AUTOSAR XML (schema 4-0-3)
standard types defined: uint8, boolean, Boolean, UInt16, UInt8
package /AUTOSAR_Platform/DataConstrs
  range DC_Boolean: raw 0..1
  range DC_UInt16: raw 0..65535
  range DC_UInt8: raw 0..255
package /DataTypes/Units
  unit NoUnit: display-name=NoUnit, factor-si-to-unit=0, offset-si-to-unit=0
package /PATAC/Facility/DataTypes/Implementation
  compu method COMPU_Boolean: 0=FALSE, 1=TRUE; unit Implementation/NoUnit
  unit NoUnit: factor-si-to-unit=1, offset-si-to-unit=0
package /PATAC/MSM/ComponentTypes
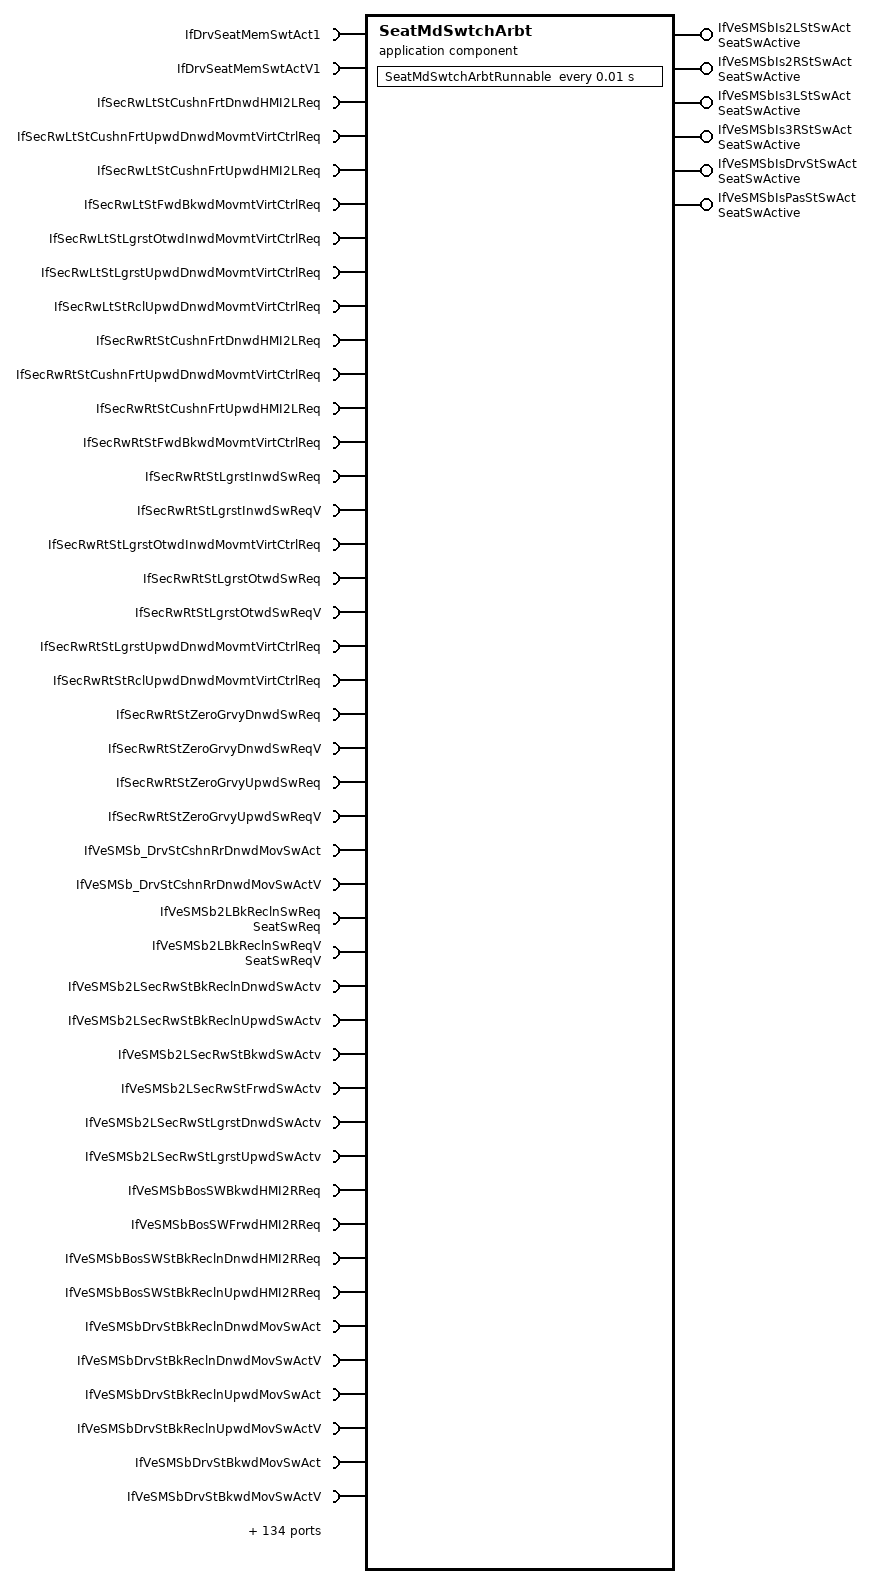
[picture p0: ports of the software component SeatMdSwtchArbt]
  application sw component type SeatMdSwtchArbt
    6 x provide port, all with provided-interface=SeatSwActive:
      IfVeSMSbIs2LStSwAct: nonqueued-sender-com-spec{data-element=SeatSwActive/Val, init-value=0}
      IfVeSMSbIs2RStSwAct: nonqueued-sender-com-spec{data-element=SeatSwActive/Val, init-value=ComSpec8990498a_9172c788e1a27a03:0}
      IfVeSMSbIs3LStSwAct: nonqueued-sender-com-spec{data-element=SeatSwActive/Val, init-value=ComSpec1be8b356_bff1fa270b850cb2:0}
      IfVeSMSbIs3RStSwAct: nonqueued-sender-com-spec{data-element=SeatSwActive/Val, init-value=ComSpec86b33b2c_4b4378d252844b5b:0}
      IfVeSMSbIsDrvStSwAct: nonqueued-sender-com-spec{data-element=SeatSwActive/Val, init-value=ComSpeccfea2e26_82ec98f59fb47201:0}
      IfVeSMSbIsPasStSwAct: nonqueued-sender-com-spec{data-element=SeatSwActive/Val, init-value=ComSpec83cefd09_a80dc45f2ed75e9c:0}
    178 x require port:
      IfDrvSeatMemSwtAct1: nonqueued-receiver-com-spec{data-element=IfDrvSeatMemSwtAct1/Val, filter=data-filter-type=ALWAYS, init-value=ComSpec097d2a70_c41c2d6baecec007:0}, required-interface=IfDrvSeatMemSwtAct1
      IfDrvSeatMemSwtActV1: nonqueued-receiver-com-spec{data-element=IfDrvSeatMemSwtActV1/Val, filter=data-filter-type=ALWAYS, init-value=ComSpece168664c_e10092eb753fba19:1}, required-interface=IfDrvSeatMemSwtActV1
      IfSecRwLtStCushnFrtDnwdHMI2LReq: nonqueued-receiver-com-spec{data-element=IfSecRwLtStCushnFrtDnwdHMI2LReq/Val, filter=data-filter-type=ALWAYS, init-value=0}, required-interface=IfSecRwLtStCushnFrtDnwdHMI2LReq
      IfSecRwLtStCushnFrtUpwdDnwdMovmtVirtCtrlReq: nonqueued-receiver-com-spec{data-element=IfSecRwLtStCushnFrtUpwdDnwdMovmtVirtCtrlReq/Val, filter=data-filter-type=ALWAYS, init-value=0}, required-interface=IfSecRwLtStCushnFrtUpwdDnwdMovmtVirtCtrlReq
      IfSecRwLtStCushnFrtUpwdHMI2LReq: nonqueued-receiver-com-spec{data-element=IfSecRwLtStCushnFrtUpwdHMI2LReq/Val, filter=data-filter-type=ALWAYS, init-value=0}, required-interface=IfSecRwLtStCushnFrtUpwdHMI2LReq
      IfSecRwLtStFwdBkwdMovmtVirtCtrlReq: nonqueued-receiver-com-spec{data-element=IfSecRwLtStFwdBkwdMovmtVirtCtrlReq/Val, filter=data-filter-type=ALWAYS, init-value=0}, required-interface=IfSecRwLtStFwdBkwdMovmtVirtCtrlReq
      IfSecRwLtStLgrstOtwdInwdMovmtVirtCtrlReq: nonqueued-receiver-com-spec{data-element=IfSecRwLtStLgrstOtwdInwdMovmtVirtCtrlReq/Val, filter=data-filter-type=ALWAYS, init-value=0}, required-interface=IfSecRwLtStLgrstOtwdInwdMovmtVirtCtrlReq
      IfSecRwLtStLgrstUpwdDnwdMovmtVirtCtrlReq: nonqueued-receiver-com-spec{data-element=IfSecRwLtStLgrstUpwdDnwdMovmtVirtCtrlReq/Val, filter=data-filter-type=ALWAYS, init-value=0}, required-interface=IfSecRwLtStLgrstUpwdDnwdMovmtVirtCtrlReq
      IfSecRwLtStRclUpwdDnwdMovmtVirtCtrlReq: nonqueued-receiver-com-spec{data-element=IfSecRwLtStRclUpwdDnwdMovmtVirtCtrlReq/Val, filter=data-filter-type=ALWAYS, init-value=0}, required-interface=IfSecRwLtStRclUpwdDnwdMovmtVirtCtrlReq
      IfSecRwRtStCushnFrtDnwdHMI2LReq: nonqueued-receiver-com-spec{data-element=IfSecRwRtStCushnFrtDnwdHMI2LReq/Val, filter=data-filter-type=ALWAYS, init-value=0}, required-interface=IfSecRwRtStCushnFrtDnwdHMI2LReq
      IfSecRwRtStCushnFrtUpwdDnwdMovmtVirtCtrlReq: nonqueued-receiver-com-spec{data-element=IfSecRwRtStCushnFrtUpwdDnwdMovmtVirtCtrlReq/Val, filter=data-filter-type=ALWAYS, init-value=0}, required-interface=IfSecRwRtStCushnFrtUpwdDnwdMovmtVirtCtrlReq
      IfSecRwRtStCushnFrtUpwdHMI2LReq: nonqueued-receiver-com-spec{data-element=IfSecRwRtStCushnFrtUpwdHMI2LReq/Val, filter=data-filter-type=ALWAYS, init-value=0}, required-interface=IfSecRwRtStCushnFrtUpwdHMI2LReq
      IfSecRwRtStFwdBkwdMovmtVirtCtrlReq: nonqueued-receiver-com-spec{data-element=IfSecRwRtStFwdBkwdMovmtVirtCtrlReq/Val, filter=data-filter-type=ALWAYS, init-value=0}, required-interface=IfSecRwRtStFwdBkwdMovmtVirtCtrlReq
      IfSecRwRtStLgrstInwdSwReq: nonqueued-receiver-com-spec{data-element=IfSecRwRtStLgrstInwdSwReq/Val, filter=data-filter-type=ALWAYS, init-value=0}, required-interface=IfSecRwRtStLgrstInwdSwReq
      IfSecRwRtStLgrstInwdSwReqV: nonqueued-receiver-com-spec{data-element=IfSecRwRtStLgrstInwdSwReqV/Val, filter=data-filter-type=ALWAYS, init-value=0}, required-interface=IfSecRwRtStLgrstInwdSwReqV
      IfSecRwRtStLgrstOtwdInwdMovmtVirtCtrlReq: nonqueued-receiver-com-spec{data-element=IfSecRwRtStLgrstOtwdInwdMovmtVirtCtrlReq/Val, filter=data-filter-type=ALWAYS, init-value=0}, required-interface=IfSecRwRtStLgrstOtwdInwdMovmtVirtCtrlReq
      IfSecRwRtStLgrstOtwdSwReq: nonqueued-receiver-com-spec{data-element=IfSecRwRtStLgrstOtwdSwReq/Val, filter=data-filter-type=ALWAYS, init-value=0}, required-interface=IfSecRwRtStLgrstOtwdSwReq
      IfSecRwRtStLgrstOtwdSwReqV: nonqueued-receiver-com-spec{data-element=IfSecRwRtStLgrstOtwdSwReqV/Val, filter=data-filter-type=ALWAYS, init-value=0}, required-interface=IfSecRwRtStLgrstOtwdSwReqV
      IfSecRwRtStLgrstUpwdDnwdMovmtVirtCtrlReq: nonqueued-receiver-com-spec{data-element=IfSecRwRtStLgrstUpwdDnwdMovmtVirtCtrlReq/Val, filter=data-filter-type=ALWAYS, init-value=0}, required-interface=IfSecRwRtStLgrstUpwdDnwdMovmtVirtCtrlReq
      IfSecRwRtStRclUpwdDnwdMovmtVirtCtrlReq: nonqueued-receiver-com-spec{data-element=IfSecRwRtStRclUpwdDnwdMovmtVirtCtrlReq/Val, filter=data-filter-type=ALWAYS, init-value=0}, required-interface=IfSecRwRtStRclUpwdDnwdMovmtVirtCtrlReq
      IfSecRwRtStZeroGrvyDnwdSwReq: nonqueued-receiver-com-spec{data-element=IfSecRwRtStZeroGrvyDnwdSwReq/Val, filter=data-filter-type=ALWAYS, init-value=0}, required-interface=IfSecRwRtStZeroGrvyDnwdSwReq
      IfSecRwRtStZeroGrvyDnwdSwReqV: nonqueued-receiver-com-spec{data-element=IfSecRwRtStZeroGrvyDnwdSwReqV/Val, filter=data-filter-type=ALWAYS, init-value=0}, required-interface=IfSecRwRtStZeroGrvyDnwdSwReqV
      IfSecRwRtStZeroGrvyUpwdSwReq: nonqueued-receiver-com-spec{data-element=IfSecRwRtStZeroGrvyUpwdSwReq/Val, filter=data-filter-type=ALWAYS, init-value=0}, required-interface=IfSecRwRtStZeroGrvyUpwdSwReq
      IfSecRwRtStZeroGrvyUpwdSwReqV: nonqueued-receiver-com-spec{data-element=IfSecRwRtStZeroGrvyUpwdSwReqV/Val, filter=data-filter-type=ALWAYS, init-value=0}, required-interface=IfSecRwRtStZeroGrvyUpwdSwReqV
      IfVeSMSb_DrvStCshnRrDnwdMovSwAct: nonqueued-receiver-com-spec{data-element=IfVeSMSb_DrvStCshnRrDnwdMovSwAct/Val, filter=data-filter-type=ALWAYS, init-value=0}, required-interface=IfVeSMSb_DrvStCshnRrDnwdMovSwAct
      IfVeSMSb_DrvStCshnRrDnwdMovSwActV: nonqueued-receiver-com-spec{data-element=IfVeSMSb_DrvStCshnRrDnwdMovSwActV/Val, filter=data-filter-type=ALWAYS, init-value=1}, required-interface=IfVeSMSb_DrvStCshnRrDnwdMovSwActV
      IfVeSMSb2LBkReclnSwReq: nonqueued-receiver-com-spec{data-element=SeatSwReq/Val, filter=data-filter-type=ALWAYS, init-value=ComSpec24bdc9f9_e94ae9a508735d5e:0}, required-interface=SeatSwReq
      IfVeSMSb2LBkReclnSwReqV: nonqueued-receiver-com-spec{data-element=SeatSwReqV/Val, filter=data-filter-type=ALWAYS, init-value=0}, required-interface=SeatSwReqV
      IfVeSMSb2LSecRwStBkReclnDnwdSwActv: nonqueued-receiver-com-spec{data-element=IfVeSMSb2LSecRwStBkReclnDnwdSwActv/Val, filter=data-filter-type=ALWAYS, init-value=0}, required-interface=IfVeSMSb2LSecRwStBkReclnDnwdSwActv
      IfVeSMSb2LSecRwStBkReclnUpwdSwActv: nonqueued-receiver-com-spec{data-element=IfVeSMSb2LSecRwStBkReclnUpwdSwActv/Val, filter=data-filter-type=ALWAYS, init-value=0}, required-interface=IfVeSMSb2LSecRwStBkReclnUpwdSwActv
      IfVeSMSb2LSecRwStBkwdSwActv: nonqueued-receiver-com-spec{data-element=IfVeSMSb2LSecRwStBkwdSwActv/Val, filter=data-filter-type=ALWAYS, init-value=0}, required-interface=IfVeSMSb2LSecRwStBkwdSwActv
      IfVeSMSb2LSecRwStFrwdSwActv: nonqueued-receiver-com-spec{data-element=IfVeSMSb2LSecRwStFrwdSwActv/Val, filter=data-filter-type=ALWAYS, init-value=0}, required-interface=IfVeSMSb2LSecRwStFrwdSwActv
      IfVeSMSb2LSecRwStLgrstDnwdSwActv: nonqueued-receiver-com-spec{data-element=IfVeSMSb2LSecRwStLgrstDnwdSwActv/Val, filter=data-filter-type=ALWAYS, init-value=0}, required-interface=IfVeSMSb2LSecRwStLgrstDnwdSwActv
      IfVeSMSb2LSecRwStLgrstUpwdSwActv: nonqueued-receiver-com-spec{data-element=IfVeSMSb2LSecRwStLgrstUpwdSwActv/Val, filter=data-filter-type=ALWAYS, init-value=0}, required-interface=IfVeSMSb2LSecRwStLgrstUpwdSwActv
      IfVeSMSbBosSWBkwdHMI2RReq: nonqueued-receiver-com-spec{data-element=IfVeSMSbBosSWBkwdHMI2RReq/Val, filter=data-filter-type=ALWAYS, init-value=0}, required-interface=IfVeSMSbBosSWBkwdHMI2RReq
      IfVeSMSbBosSWFrwdHMI2RReq: nonqueued-receiver-com-spec{data-element=IfVeSMSbBosSWFrwdHMI2RReq/Val, filter=data-filter-type=ALWAYS, init-value=0}, required-interface=IfVeSMSbBosSWFrwdHMI2RReq
      IfVeSMSbBosSWStBkReclnDnwdHMI2RReq: nonqueued-receiver-com-spec{data-element=IfVeSMSbBosSWStBkReclnDnwdHMI2RReq/Val, filter=data-filter-type=ALWAYS, init-value=0}, required-interface=IfVeSMSbBosSWStBkReclnDnwdHMI2RReq
      IfVeSMSbBosSWStBkReclnUpwdHMI2RReq: nonqueued-receiver-com-spec{data-element=IfVeSMSbBosSWStBkReclnUpwdHMI2RReq/Val, filter=data-filter-type=ALWAYS, init-value=0}, required-interface=IfVeSMSbBosSWStBkReclnUpwdHMI2RReq
      IfVeSMSbDrvStBkReclnDnwdMovSwAct: nonqueued-receiver-com-spec{data-element=IfVeSMSbDrvStBkReclnDnwdMovSwAct/Val, filter=data-filter-type=ALWAYS, init-value=0}, required-interface=IfVeSMSbDrvStBkReclnDnwdMovSwAct
      IfVeSMSbDrvStBkReclnDnwdMovSwActV: nonqueued-receiver-com-spec{data-element=IfVeSMSbDrvStBkReclnDnwdMovSwActV/Val, filter=data-filter-type=ALWAYS, init-value=0}, required-interface=IfVeSMSbDrvStBkReclnDnwdMovSwActV
      IfVeSMSbDrvStBkReclnUpwdMovSwAct: nonqueued-receiver-com-spec{data-element=IfVeSMSbDrvStBkReclnUpwdMovSwAct/Val, filter=data-filter-type=ALWAYS, init-value=0}, required-interface=IfVeSMSbDrvStBkReclnUpwdMovSwAct
      IfVeSMSbDrvStBkReclnUpwdMovSwActV: nonqueued-receiver-com-spec{data-element=IfVeSMSbDrvStBkReclnUpwdMovSwActV/Val, filter=data-filter-type=ALWAYS, init-value=1}, required-interface=IfVeSMSbDrvStBkReclnUpwdMovSwActV
      IfVeSMSbDrvStBkwdMovSwAct: nonqueued-receiver-com-spec{data-element=IfVeSMSbDrvStBkwdMovSwAct/Val, filter=data-filter-type=ALWAYS, init-value=0}, required-interface=IfVeSMSbDrvStBkwdMovSwAct
      IfVeSMSbDrvStBkwdMovSwActV: nonqueued-receiver-com-spec{data-element=IfVeSMSbDrvStBkwdMovSwActV/Val, filter=data-filter-type=ALWAYS, init-value=1}, required-interface=IfVeSMSbDrvStBkwdMovSwActV
      IfVeSMSbDrvStCshnFrntDnwdMovSwAct: nonqueued-receiver-com-spec{data-element=IfVeSMSbDrvStCshnFrntDnwdMovSwAct/Val, filter=data-filter-type=ALWAYS, init-value=0}, required-interface=IfVeSMSbDrvStCshnFrntDnwdMovSwAct
      IfVeSMSbDrvStCshnFrntDnwdMovSwActV: nonqueued-receiver-com-spec{data-element=IfVeSMSbDrvStCshnFrntDnwdMovSwActV/Val, filter=data-filter-type=ALWAYS, init-value=1}, required-interface=IfVeSMSbDrvStCshnFrntDnwdMovSwActV
      IfVeSMSbDrvStCshnFrntUpwdMovSwAct: nonqueued-receiver-com-spec{data-element=IfVeSMSbDrvStCshnFrntUpwdMovSwAct/Val, filter=data-filter-type=ALWAYS, init-value=0}, required-interface=IfVeSMSbDrvStCshnFrntUpwdMovSwAct
      IfVeSMSbDrvStCshnFrntUpwdMovSwActV: nonqueued-receiver-com-spec{data-element=IfVeSMSbDrvStCshnFrntUpwdMovSwActV/Val, filter=data-filter-type=ALWAYS, init-value=1}, required-interface=IfVeSMSbDrvStCshnFrntUpwdMovSwActV
      IfVeSMSbDrvStCshnRrUpwdMovSwAct: nonqueued-receiver-com-spec{data-element=IfVeSMSbDrvStCshnRrUpwdMovSwAct/Val, filter=data-filter-type=ALWAYS, init-value=0}, required-interface=IfVeSMSbDrvStCshnRrUpwdMovSwAct
      IfVeSMSbDrvStCshnRrUpwdMovSwActV: nonqueued-receiver-com-spec{data-element=IfVeSMSbDrvStCshnRrUpwdMovSwActV/Val, filter=data-filter-type=ALWAYS, init-value=0}, required-interface=IfVeSMSbDrvStCshnRrUpwdMovSwActV
      IfVeSMSbDrvStFrwdMovSwAct: nonqueued-receiver-com-spec{data-element=IfVeSMSbDrvStFrwdMovSwAct/Val, filter=data-filter-type=ALWAYS, init-value=0}, required-interface=IfVeSMSbDrvStFrwdMovSwAct
      IfVeSMSbDrvStFrwdMovSwActV: nonqueued-receiver-com-spec{data-element=IfVeSMSbDrvStFrwdMovSwActV/Val, filter=data-filter-type=ALWAYS, init-value=1}, required-interface=IfVeSMSbDrvStFrwdMovSwActV
      IfVeSMSbPassStBkReclnDnwdMovBosSwAct: nonqueued-receiver-com-spec{data-element=IfVeSMSbPassStBkReclnDnwdMovBosSwAct/Val, filter=data-filter-type=ALWAYS, init-value=0}, required-interface=IfVeSMSbPassStBkReclnDnwdMovBosSwAct
      IfVeSMSbPassStBkReclnDnwdMovBosSwActV: nonqueued-receiver-com-spec{data-element=IfVeSMSbPassStBkReclnDnwdMovBosSwActV/Val, filter=data-filter-type=ALWAYS, init-value=0}, required-interface=IfVeSMSbPassStBkReclnDnwdMovBosSwActV
      IfVeSMSbPassStBkReclnDnwdMovSwAct: nonqueued-receiver-com-spec{data-element=IfVeSMSbPassStBkReclnDnwdMovSwAct/Val, filter=data-filter-type=ALWAYS, init-value=0}, required-interface=IfVeSMSbPassStBkReclnDnwdMovSwAct
      IfVeSMSbPassStBkReclnDnwdMovSwActV: nonqueued-receiver-com-spec{data-element=IfVeSMSbPassStBkReclnDnwdMovSwActV/Val, filter=data-filter-type=ALWAYS, init-value=0}, required-interface=IfVeSMSbPassStBkReclnDnwdMovSwActV
      IfVeSMSbPassStBkReclnUpwdMovBosSwAct: nonqueued-receiver-com-spec{data-element=IfVeSMSbPassStBkReclnUpwdMovBosSwAct/Val, filter=data-filter-type=ALWAYS, init-value=0}, required-interface=IfVeSMSbPassStBkReclnUpwdMovBosSwAct
      IfVeSMSbPassStBkReclnUpwdMovBosSwActV: nonqueued-receiver-com-spec{data-element=IfVeSMSbPassStBkReclnUpwdMovBosSwActV/Val, filter=data-filter-type=ALWAYS, init-value=0}, required-interface=IfVeSMSbPassStBkReclnUpwdMovBosSwActV
      IfVeSMSbPassStBkReclnUpwdMovSwAct: nonqueued-receiver-com-spec{data-element=IfVeSMSbPassStBkReclnUpwdMovSwAct/Val, filter=data-filter-type=ALWAYS, init-value=0}, required-interface=IfVeSMSbPassStBkReclnUpwdMovSwAct
      IfVeSMSbPassStBkReclnUpwdMovSwActV: nonqueued-receiver-com-spec{data-element=IfVeSMSbPassStBkReclnUpwdMovSwActV/Val, filter=data-filter-type=ALWAYS, init-value=0}, required-interface=IfVeSMSbPassStBkReclnUpwdMovSwActV
      IfVeSMSbPassStBkwdMovBosSwAct: nonqueued-receiver-com-spec{data-element=IfVeSMSbPassStBkwdMovBosSwAct/Val, filter=data-filter-type=ALWAYS, init-value=0}, required-interface=IfVeSMSbPassStBkwdMovBosSwAct
      IfVeSMSbPassStBkwdMovBosSwActV: nonqueued-receiver-com-spec{data-element=IfVeSMSbPassStBkwdMovBosSwActV/Val, filter=data-filter-type=ALWAYS, init-value=0}, required-interface=IfVeSMSbPassStBkwdMovBosSwActV
      IfVeSMSbPassStBkwdMovSwAct: nonqueued-receiver-com-spec{data-element=IfVeSMSbPassStBkwdMovSwAct/Val, filter=data-filter-type=ALWAYS, init-value=0}, required-interface=IfVeSMSbPassStBkwdMovSwAct
      IfVeSMSbPassStBkwdMovSwActV: nonqueued-receiver-com-spec{data-element=IfVeSMSbPassStBkwdMovSwActV/Val, filter=data-filter-type=ALWAYS, init-value=0}, required-interface=IfVeSMSbPassStBkwdMovSwActV
      IfVeSMSbPassStCshnFrntDnwdMovSwAct: nonqueued-receiver-com-spec{data-element=IfVeSMSbPassStCshnFrntDnwdMovSwAct/Val, filter=data-filter-type=ALWAYS, init-value=0}, required-interface=IfVeSMSbPassStCshnFrntDnwdMovSwAct
      IfVeSMSbPassStCshnFrntDnwdMovSwActV: nonqueued-receiver-com-spec{data-element=IfVeSMSbPassStCshnFrntDnwdMovSwActV/Val, filter=data-filter-type=ALWAYS, init-value=0}, required-interface=IfVeSMSbPassStCshnFrntDnwdMovSwActV
      IfVeSMSbPassStCshnFrntUpwdMovSwAct: nonqueued-receiver-com-spec{data-element=IfVeSMSbPassStCshnFrntUpwdMovSwAct/Val, filter=data-filter-type=ALWAYS, init-value=0}, required-interface=IfVeSMSbPassStCshnFrntUpwdMovSwAct
      IfVeSMSbPassStCshnFrntUpwdMovSwActV: nonqueued-receiver-com-spec{data-element=IfVeSMSbPassStCshnFrntUpwdMovSwActV/Val, filter=data-filter-type=ALWAYS, init-value=0}, required-interface=IfVeSMSbPassStCshnFrntUpwdMovSwActV
      IfVeSMSbPassStCshnRrDnwdMovSwAct: nonqueued-receiver-com-spec{data-element=IfVeSMSbPassStCshnRrDnwdMovSwAct/Val, filter=data-filter-type=ALWAYS, init-value=0}, required-interface=IfVeSMSbPassStCshnRrDnwdMovSwAct
      IfVeSMSbPassStCshnRrDnwdMovSwActV: nonqueued-receiver-com-spec{data-element=IfVeSMSbPassStCshnRrDnwdMovSwActV/Val, filter=data-filter-type=ALWAYS, init-value=0}, required-interface=IfVeSMSbPassStCshnRrDnwdMovSwActV
      IfVeSMSbPassStCshnRrUpwdMovSwAct: nonqueued-receiver-com-spec{data-element=IfVeSMSbPassStCshnRrUpwdMovSwAct/Val, filter=data-filter-type=ALWAYS, init-value=0}, required-interface=IfVeSMSbPassStCshnRrUpwdMovSwAct
      IfVeSMSbPassStCshnRrUpwdMovSwActV: nonqueued-receiver-com-spec{data-element=IfVeSMSbPassStCshnRrUpwdMovSwActV/Val, filter=data-filter-type=ALWAYS, init-value=0}, required-interface=IfVeSMSbPassStCshnRrUpwdMovSwActV
      IfVeSMSbPassStFrwdMovBosSwAct: nonqueued-receiver-com-spec{data-element=IfVeSMSbPassStFrwdMovBosSwAct/Val, filter=data-filter-type=ALWAYS, init-value=0}, required-interface=IfVeSMSbPassStFrwdMovBosSwAct
      IfVeSMSbPassStFrwdMovBosSwActV: nonqueued-receiver-com-spec{data-element=IfVeSMSbPassStFrwdMovBosSwActV/Val, filter=data-filter-type=ALWAYS, init-value=0}, required-interface=IfVeSMSbPassStFrwdMovBosSwActV
      IfVeSMSbPassStFrwdMovSwAct: nonqueued-receiver-com-spec{data-element=IfVeSMSbPassStFrwdMovSwAct/Val, filter=data-filter-type=ALWAYS, init-value=0}, required-interface=IfVeSMSbPassStFrwdMovSwAct
      IfVeSMSbPassStFrwdMovSwActV: nonqueued-receiver-com-spec{data-element=IfVeSMSbPassStFrwdMovSwActV/Val, filter=data-filter-type=ALWAYS, init-value=0}, required-interface=IfVeSMSbPassStFrwdMovSwActV
      IfVeSMSbRrLtStFtDnwdHMI2LReq: nonqueued-receiver-com-spec{data-element=SeatHMIReq/Val, filter=data-filter-type=ALWAYS, init-value=0}, required-interface=SeatHMIReq
      IfVeSMSbRrLtStFtUpwdHMI2LReq: nonqueued-receiver-com-spec{data-element=SeatHMIReq/Val, filter=data-filter-type=ALWAYS, init-value=ComSpec97c51aec_3141e7a252aa16ce:0}, required-interface=SeatHMIReq
      IfVeSMSbRrPsgComprtStBkReclnDnwdSwReq: nonqueued-receiver-com-spec{data-element=IfVeSMSbRrPsgComprtStBkReclnDnwdSwReq/Val, filter=data-filter-type=ALWAYS, init-value=0}, required-interface=IfVeSMSbRrPsgComprtStBkReclnDnwdSwReq
      IfVeSMSbRrPsgComprtStBkReclnDnwdSwReqV: nonqueued-receiver-com-spec{data-element=IfVeSMSbRrPsgComprtStBkReclnDnwdSwReqV/Val, filter=data-filter-type=ALWAYS, init-value=0}, required-interface=IfVeSMSbRrPsgComprtStBkReclnDnwdSwReqV
      IfVeSMSbRrPsgComprtStBkReclnUpwdSwReq: nonqueued-receiver-com-spec{data-element=IfVeSMSbRrPsgComprtStBkReclnUpwdSwReq/Val, filter=data-filter-type=ALWAYS, init-value=0}, required-interface=IfVeSMSbRrPsgComprtStBkReclnUpwdSwReq
      IfVeSMSbRrPsgComprtStBkReclnUpwdSwReqV: nonqueued-receiver-com-spec{data-element=IfVeSMSbRrPsgComprtStBkReclnUpwdSwReqV/Val, filter=data-filter-type=ALWAYS, init-value=0}, required-interface=IfVeSMSbRrPsgComprtStBkReclnUpwdSwReqV
      IfVeSMSbRrPsgComprtStBkwdSwReq: nonqueued-receiver-com-spec{data-element=IfVeSMSbRrPsgComprtStBkwdSwReq/Val, filter=data-filter-type=ALWAYS, init-value=0}, required-interface=IfVeSMSbRrPsgComprtStBkwdSwReq
      IfVeSMSbRrPsgComprtStBkwdSwReqV: nonqueued-receiver-com-spec{data-element=IfVeSMSbRrPsgComprtStBkwdSwReqV/Val, filter=data-filter-type=ALWAYS, init-value=0}, required-interface=IfVeSMSbRrPsgComprtStBkwdSwReqV
      IfVeSMSbRrPsgComprtStFrwdSwReq: nonqueued-receiver-com-spec{data-element=IfVeSMSbRrPsgComprtStFrwdSwReq/Val, filter=data-filter-type=ALWAYS, init-value=0}, required-interface=IfVeSMSbRrPsgComprtStFrwdSwReq
      IfVeSMSbRrPsgComprtStFrwdSwReqV: nonqueued-receiver-com-spec{data-element=IfVeSMSbRrPsgComprtStFrwdSwReqV/Val, filter=data-filter-type=ALWAYS, init-value=0}, required-interface=IfVeSMSbRrPsgComprtStFrwdSwReqV
      IfVeSMSbRrRtStFtDnwdHMI2RReq: nonqueued-receiver-com-spec{data-element=SeatHMIReq/Val, filter=data-filter-type=ALWAYS, init-value=ComSpec0bdc9f86_aabb875c463cd197:0}, required-interface=SeatHMIReq
      IfVeSMSbRrRtStFtUpwdHMI2RReq: nonqueued-receiver-com-spec{data-element=SeatHMIReq/Val, filter=data-filter-type=ALWAYS, init-value=ComSpec1f7bd894_e018af46480e36c8:0}, required-interface=SeatHMIReq
      IfVeSMSbSecRwLtStArmScrnHMI2LReq: nonqueued-receiver-com-spec{data-element=IfVeSMSbSecRwLtStArmScrnHMI2LReq/Val, filter=data-filter-type=ALWAYS, init-value=0}, required-interface=IfVeSMSbSecRwLtStArmScrnHMI2LReq
      IfVeSMSbSecRwLtStBkReclnDnwdHMI2LReq: nonqueued-receiver-com-spec{data-element=IfVeSMSbSecRwLtStBkReclnDnwdHMI2LReq/Val, filter=data-filter-type=ALWAYS, init-value=0}, required-interface=IfVeSMSbSecRwLtStBkReclnDnwdHMI2LReq
      IfVeSMSbSecRwLtStBkReclnUpwdHMI2LReq: nonqueued-receiver-com-spec{data-element=IfVeSMSbSecRwLtStBkReclnUpwdHMI2LReq/Val, filter=data-filter-type=ALWAYS, init-value=0}, required-interface=IfVeSMSbSecRwLtStBkReclnUpwdHMI2LReq
      IfVeSMSbSecRwLtStBkwdHMI2LReq: nonqueued-receiver-com-spec{data-element=IfVeSMSbSecRwLtStBkwdHMI2LReq/Val, filter=data-filter-type=ALWAYS, init-value=0}, required-interface=IfVeSMSbSecRwLtStBkwdHMI2LReq
      IfVeSMSbSecRwLtStFrwdHMI2LReq: nonqueued-receiver-com-spec{data-element=IfVeSMSbSecRwLtStFrwdHMI2LReq/Val, filter=data-filter-type=ALWAYS, init-value=0}, required-interface=IfVeSMSbSecRwLtStFrwdHMI2LReq
      IfVeSMSbSecRwLtStFtClsHMI2LReq: nonqueued-receiver-com-spec{data-element=IfVeSMSbSecRwLtStFtClsHMI2LReq/Val, filter=data-filter-type=ALWAYS, init-value=0}, required-interface=IfVeSMSbSecRwLtStFtClsHMI2LReq
      IfVeSMSbSecRwLtStFtDnwdHMI2LReq: nonqueued-receiver-com-spec{data-element=IfVeSMSbSecRwLtStFtDnwdHMI2LReq/Val, filter=data-filter-type=ALWAYS, init-value=0}, required-interface=IfVeSMSbSecRwLtStFtDnwdHMI2LReq
      IfVeSMSbSecRwLtStFtOpenHMI2LReq: nonqueued-receiver-com-spec{data-element=IfVeSMSbSecRwLtStFtOpenHMI2LReq/Val, filter=data-filter-type=ALWAYS, init-value=0}, required-interface=IfVeSMSbSecRwLtStFtOpenHMI2LReq
      IfVeSMSbSecRwLtStFtUpwdHMI2LReq: nonqueued-receiver-com-spec{data-element=IfVeSMSbSecRwLtStFtUpwdHMI2LReq/Val, filter=data-filter-type=ALWAYS, init-value=0}, required-interface=IfVeSMSbSecRwLtStFtUpwdHMI2LReq
      IfVeSMSbSecRwLtStHdrstBkwdHMI2LReq: nonqueued-receiver-com-spec{data-element=SeatHMIReq/Val, filter=data-filter-type=ALWAYS, init-value=ComSpec0167f82a_856251cd950cbae8:0}, required-interface=SeatHMIReq
      IfVeSMSbSecRwLtStHdrstDnwdHMI2LReq: nonqueued-receiver-com-spec{data-element=IfVeSMSbSecRwLtStHdrstDnwdHMI2LReq/Val, filter=data-filter-type=ALWAYS, init-value=0}, required-interface=IfVeSMSbSecRwLtStHdrstDnwdHMI2LReq
      IfVeSMSbSecRwLtStHdrstFrwdHMI2LReq: nonqueued-receiver-com-spec{data-element=SeatHMIReq/Val, filter=data-filter-type=ALWAYS, init-value=ComSpec5f42d522_eba982f5ab37eb2d:0}, required-interface=SeatHMIReq
      IfVeSMSbSecRwLtStHdrstUpwdHMI2LReq: nonqueued-receiver-com-spec{data-element=IfVeSMSbSecRwLtStHdrstUpwdHMI2LReq/Val, filter=data-filter-type=ALWAYS, init-value=0}, required-interface=IfVeSMSbSecRwLtStHdrstUpwdHMI2LReq
      IfVeSMSbSecRwLtStLcMovActv: nonqueued-receiver-com-spec{data-element=IfVeSMSbSecRwLtStLcMovActv/Val, filter=data-filter-type=ALWAYS, init-value=0}, required-interface=IfVeSMSbSecRwLtStLcMovActv
      IfVeSMSbSecRwLtStLgrstDnwdHMI2LReq: nonqueued-receiver-com-spec{data-element=IfVeSMSbSecRwLtStLgrstDnwdHMI2LReq/Val, filter=data-filter-type=ALWAYS, init-value=0}, required-interface=IfVeSMSbSecRwLtStLgrstDnwdHMI2LReq
      IfVeSMSbSecRwLtStLgrstInwdHMI2LReq: nonqueued-receiver-com-spec{data-element=SeatHMIReq/Val, filter=data-filter-type=ALWAYS, init-value=ComSpec391ef544_49d43dd356230b81:0}, required-interface=SeatHMIReq
      IfVeSMSbSecRwLtStLgrstOtwdHMI2LReq: nonqueued-receiver-com-spec{data-element=SeatHMIReq/Val, filter=data-filter-type=ALWAYS, init-value=ComSpec6a9a1890_11348f734d932b0c:0}, required-interface=SeatHMIReq
      IfVeSMSbSecRwLtStLgrstUpwdHMI2LReq: nonqueued-receiver-com-spec{data-element=IfVeSMSbSecRwLtStLgrstUpwdHMI2LReq/Val, filter=data-filter-type=ALWAYS, init-value=0}, required-interface=IfVeSMSbSecRwLtStLgrstUpwdHMI2LReq
      IfVeSMSbSecRwLtStLtwdHMI2LReq: nonqueued-receiver-com-spec{data-element=IfVeSMSbSecRwLtStLtwdHMI2LReq/Val, filter=data-filter-type=ALWAYS, init-value=0}, required-interface=IfVeSMSbSecRwLtStLtwdHMI2LReq
      IfVeSMSbSecRwLtStRtwdHMI2LReq: nonqueued-receiver-com-spec{data-element=IfVeSMSbSecRwLtStRtwdHMI2LReq/Val, filter=data-filter-type=ALWAYS, init-value=0}, required-interface=IfVeSMSbSecRwLtStRtwdHMI2LReq
      IfVeSMSbSecRwRtStArmScrnHMI2RReq: nonqueued-receiver-com-spec{data-element=IfVeSMSbSecRwRtStArmScrnHMI2RReq/Val, filter=data-filter-type=ALWAYS, init-value=0}, required-interface=IfVeSMSbSecRwRtStArmScrnHMI2RReq
      IfVeSMSbSecRwRtStBkReclnDnwdHMI2RReq: nonqueued-receiver-com-spec{data-element=IfVeSMSbSecRwRtStBkReclnDnwdHMI2RReq/Val, filter=data-filter-type=ALWAYS, init-value=0}, required-interface=IfVeSMSbSecRwRtStBkReclnDnwdHMI2RReq
      IfVeSMSbSecRwRtStBkReclnDnwdSwReq: nonqueued-receiver-com-spec{data-element=IfVeSMSbSecRwRtStBkReclnDnwdSwReq/Val, filter=data-filter-type=ALWAYS, init-value=0}, required-interface=IfVeSMSbSecRwRtStBkReclnDnwdSwReq
      IfVeSMSbSecRwRtStBkReclnDnwdSwReqV: nonqueued-receiver-com-spec{data-element=IfVeSMSbSecRwRtStBkReclnDnwdSwReqV/Val, filter=data-filter-type=ALWAYS, init-value=0}, required-interface=IfVeSMSbSecRwRtStBkReclnDnwdSwReqV
      IfVeSMSbSecRwRtStBkReclnUpwdHMI2RReq: nonqueued-receiver-com-spec{data-element=IfVeSMSbSecRwRtStBkReclnUpwdHMI2RReq/Val, filter=data-filter-type=ALWAYS, init-value=0}, required-interface=IfVeSMSbSecRwRtStBkReclnUpwdHMI2RReq
      IfVeSMSbSecRwRtStBkReclnUpwdSwReq: nonqueued-receiver-com-spec{data-element=IfVeSMSbSecRwRtStBkReclnUpwdSwReq/Val, filter=data-filter-type=ALWAYS, init-value=0}, required-interface=IfVeSMSbSecRwRtStBkReclnUpwdSwReq
      IfVeSMSbSecRwRtStBkReclnUpwdSwReqV: nonqueued-receiver-com-spec{data-element=IfVeSMSbSecRwRtStBkReclnUpwdSwReqV/Val, filter=data-filter-type=ALWAYS, init-value=0}, required-interface=IfVeSMSbSecRwRtStBkReclnUpwdSwReqV
      IfVeSMSbSecRwRtStBkwdHMI2RReq: nonqueued-receiver-com-spec{data-element=IfVeSMSbSecRwRtStBkwdHMI2RReq/Val, filter=data-filter-type=ALWAYS, init-value=0}, required-interface=IfVeSMSbSecRwRtStBkwdHMI2RReq
      IfVeSMSbSecRwRtStBkwdSwReq: nonqueued-receiver-com-spec{data-element=IfVeSMSbSecRwRtStBkwdSwReq/Val, filter=data-filter-type=ALWAYS, init-value=0}, required-interface=IfVeSMSbSecRwRtStBkwdSwReq
      IfVeSMSbSecRwRtStBkwdSwReqV: nonqueued-receiver-com-spec{data-element=IfVeSMSbSecRwRtStBkwdSwReqV/Val, filter=data-filter-type=ALWAYS, init-value=0}, required-interface=IfVeSMSbSecRwRtStBkwdSwReqV
      IfVeSMSbSecRwRtStFrwdHMI2RReq: nonqueued-receiver-com-spec{data-element=IfVeSMSbSecRwRtStFrwdHMI2RReq/Val, filter=data-filter-type=ALWAYS, init-value=0}, required-interface=IfVeSMSbSecRwRtStFrwdHMI2RReq
      IfVeSMSbSecRwRtStFrwdSwReq: nonqueued-receiver-com-spec{data-element=IfVeSMSbSecRwRtStFrwdSwReq/Val, filter=data-filter-type=ALWAYS, init-value=0}, required-interface=IfVeSMSbSecRwRtStFrwdSwReq
      IfVeSMSbSecRwRtStFrwdSwReqV: nonqueued-receiver-com-spec{data-element=IfVeSMSbSecRwRtStFrwdSwReqV/Val, filter=data-filter-type=ALWAYS, init-value=0}, required-interface=IfVeSMSbSecRwRtStFrwdSwReqV
      IfVeSMSbSecRwRtStFtClsHMI2LReq: nonqueued-receiver-com-spec{data-element=IfVeSMSbSecRwRtStFtClsHMI2LReq/Val, filter=data-filter-type=ALWAYS, init-value=0}, required-interface=IfVeSMSbSecRwRtStFtClsHMI2LReq
      IfVeSMSbSecRwRtStFtDnwdHMI2RReq: nonqueued-receiver-com-spec{data-element=IfVeSMSbSecRwRtStFtDnwdHMI2RReq/Val, filter=data-filter-type=ALWAYS, init-value=0}, required-interface=IfVeSMSbSecRwRtStFtDnwdHMI2RReq
      IfVeSMSbSecRwRtStFtOpenHMI2LReq: nonqueued-receiver-com-spec{data-element=IfVeSMSbSecRwRtStFtOpenHMI2LReq/Val, filter=data-filter-type=ALWAYS, init-value=0}, required-interface=IfVeSMSbSecRwRtStFtOpenHMI2LReq
      IfVeSMSbSecRwRtStFtUpwdHMI2RReq: nonqueued-receiver-com-spec{data-element=IfVeSMSbSecRwRtStFtUpwdHMI2RReq/Val, filter=data-filter-type=ALWAYS, init-value=0}, required-interface=IfVeSMSbSecRwRtStFtUpwdHMI2RReq
      IfVeSMSbSecRwRtStHdrstBkwdHMI2RReq: nonqueued-receiver-com-spec{data-element=SeatHMIReq/Val, filter=data-filter-type=ALWAYS, init-value=ComSpeceee0fb2d_4b52d809fe7512ff:0}, required-interface=SeatHMIReq
      IfVeSMSbSecRwRtStHdrstDnwdHMI2RReq: nonqueued-receiver-com-spec{data-element=IfVeSMSbSecRwRtStHdrstDnwdHMI2RReq/Val, filter=data-filter-type=ALWAYS, init-value=0}, required-interface=IfVeSMSbSecRwRtStHdrstDnwdHMI2RReq
      IfVeSMSbSecRwRtStHdrstFrwdHMI2RReq: nonqueued-receiver-com-spec{data-element=SeatHMIReq/Val, filter=data-filter-type=ALWAYS, init-value=ComSpec41cf77f6_e1863cc162f0a164:0}, required-interface=SeatHMIReq
      IfVeSMSbSecRwRtStHdrstUpwdHMI2RReq: nonqueued-receiver-com-spec{data-element=IfVeSMSbSecRwRtStHdrstUpwdHMI2RReq/Val, filter=data-filter-type=ALWAYS, init-value=0}, required-interface=IfVeSMSbSecRwRtStHdrstUpwdHMI2RReq
      IfVeSMSbSecRwRtStLgrstDnwdHMI2RReq: nonqueued-receiver-com-spec{data-element=IfVeSMSbSecRwRtStLgrstDnwdHMI2RReq/Val, filter=data-filter-type=ALWAYS, init-value=0}, required-interface=IfVeSMSbSecRwRtStLgrstDnwdHMI2RReq
      IfVeSMSbSecRwRtStLgrstDnwdSwReq: nonqueued-receiver-com-spec{data-element=IfVeSMSbSecRwRtStLgrstDnwdSwReq/Val, filter=data-filter-type=ALWAYS, init-value=0}, required-interface=IfVeSMSbSecRwRtStLgrstDnwdSwReq
      IfVeSMSbSecRwRtStLgrstDnwdSwReqV: nonqueued-receiver-com-spec{data-element=IfVeSMSbSecRwRtStLgrstDnwdSwReqV/Val, filter=data-filter-type=ALWAYS, init-value=0}, required-interface=IfVeSMSbSecRwRtStLgrstDnwdSwReqV
      IfVeSMSbSecRwRtStLgrstInwdHMI2RReq: nonqueued-receiver-com-spec{data-element=SeatHMIReq/Val, filter=data-filter-type=ALWAYS, init-value=0}, required-interface=SeatHMIReq
      IfVeSMSbSecRwRtStLgrstOtwdHMI2RReq: nonqueued-receiver-com-spec{data-element=SeatHMIReq/Val, filter=data-filter-type=ALWAYS, init-value=0}, required-interface=SeatHMIReq
      IfVeSMSbSecRwRtStLgrstUpwdHMI2RReq: nonqueued-receiver-com-spec{data-element=IfVeSMSbSecRwRtStLgrstUpwdHMI2RReq/Val, filter=data-filter-type=ALWAYS, init-value=0}, required-interface=IfVeSMSbSecRwRtStLgrstUpwdHMI2RReq
      IfVeSMSbSecRwRtStLgrstUpwdSwReq: nonqueued-receiver-com-spec{data-element=IfVeSMSbSecRwRtStLgrstUpwdSwReq/Val, filter=data-filter-type=ALWAYS, init-value=0}, required-interface=IfVeSMSbSecRwRtStLgrstUpwdSwReq
      IfVeSMSbSecRwRtStLgrstUpwdSwReqV: nonqueued-receiver-com-spec{data-element=IfVeSMSbSecRwRtStLgrstUpwdSwReqV/Val, filter=data-filter-type=ALWAYS, init-value=0}, required-interface=IfVeSMSbSecRwRtStLgrstUpwdSwReqV
      IfVeSMSbSecRwRtStLmbrHMI2RReq: nonqueued-receiver-com-spec{data-element=IfVeSMSbSecRwRtStLmbrHMI2RReq/Val, filter=data-filter-type=ALWAYS, init-value=ComSpeceaf23174_ba0692c4bbc9c5d3:0}, required-interface=IfVeSMSbSecRwRtStLmbrHMI2RReq
      IfVeSMSbSecRwRtStLtwdHMI2RReq: nonqueued-receiver-com-spec{data-element=IfVeSMSbSecRwRtStLtwdHMI2RReq/Val, filter=data-filter-type=ALWAYS, init-value=0}, required-interface=IfVeSMSbSecRwRtStLtwdHMI2RReq
      IfVeSMSbSecRwRtStRtwdHMI2RReq: nonqueued-receiver-com-spec{data-element=IfVeSMSbSecRwRtStRtwdHMI2RReq/Val, filter=data-filter-type=ALWAYS, init-value=0}, required-interface=IfVeSMSbSecRwRtStRtwdHMI2RReq
      IfVeSMSbThdRLtStExpdSwReq: nonqueued-receiver-com-spec{data-element=IfVeSMSbThdRLtStExpdSwReq/Val, filter=data-filter-type=ALWAYS, init-value=0}, required-interface=IfVeSMSbThdRLtStExpdSwReq
      IfVeSMSbThdRLtStExpdSwReqV: nonqueued-receiver-com-spec{data-element=IfVeSMSbThdRLtStExpdSwReqV/Val, filter=data-filter-type=ALWAYS, init-value=0}, required-interface=IfVeSMSbThdRLtStExpdSwReqV
      IfVeSMSbThdRRtStExpdSwReq: nonqueued-receiver-com-spec{data-element=IfVeSMSbThdRRtStExpdSwReq/Val, filter=data-filter-type=ALWAYS, init-value=0}, required-interface=IfVeSMSbThdRRtStExpdSwReq
      IfVeSMSbThdRRtStExpdSwReqV: nonqueued-receiver-com-spec{data-element=IfVeSMSbThdRRtStExpdSwReqV/Val, filter=data-filter-type=ALWAYS, init-value=0}, required-interface=IfVeSMSbThdRRtStExpdSwReqV
      IfVeSMSbThdRwLtStBkReclnDnwdSwReq: nonqueued-receiver-com-spec{data-element=IfVeSMSbThdRwLtStBkReclnDnwdSwReq/Val, filter=data-filter-type=ALWAYS, init-value=0}, required-interface=IfVeSMSbThdRwLtStBkReclnDnwdSwReq
      IfVeSMSbThdRwLtStBkReclnDnwdSwReqV: nonqueued-receiver-com-spec{data-element=IfVeSMSbThdRwLtStBkReclnDnwdSwReqV/Val, filter=data-filter-type=ALWAYS, init-value=0}, required-interface=IfVeSMSbThdRwLtStBkReclnDnwdSwReqV
      IfVeSMSbThdRwLtStBkReclnUpwdSwReq: nonqueued-receiver-com-spec{data-element=IfVeSMSbThdRwLtStBkReclnUpwdSwReq/Val, filter=data-filter-type=ALWAYS, init-value=0}, required-interface=IfVeSMSbThdRwLtStBkReclnUpwdSwReq
      IfVeSMSbThdRwLtStBkReclnUpwdSwReqV: nonqueued-receiver-com-spec{data-element=IfVeSMSbThdRwLtStBkReclnUpwdSwReqV/Val, filter=data-filter-type=ALWAYS, init-value=0}, required-interface=IfVeSMSbThdRwLtStBkReclnUpwdSwReqV
      IfVeSMSbThdRwLtStBkwdSwReq: nonqueued-receiver-com-spec{data-element=IfVeSMSbThdRwLtStBkwdSwReq/Val, filter=data-filter-type=ALWAYS, init-value=0}, required-interface=IfVeSMSbThdRwLtStBkwdSwReq
      IfVeSMSbThdRwLtStBkwdSwReqV: nonqueued-receiver-com-spec{data-element=IfVeSMSbThdRwLtStBkwdSwReqV/Val, filter=data-filter-type=ALWAYS, init-value=0}, required-interface=IfVeSMSbThdRwLtStBkwdSwReqV
      IfVeSMSbThdRwLtStFrwdSwReq: nonqueued-receiver-com-spec{data-element=IfVeSMSbThdRwLtStFrwdSwReq/Val, filter=data-filter-type=ALWAYS, init-value=0}, required-interface=IfVeSMSbThdRwLtStFrwdSwReq
      IfVeSMSbThdRwLtStFrwdSwReqV: nonqueued-receiver-com-spec{data-element=IfVeSMSbThdRwLtStFrwdSwReqV/Val, filter=data-filter-type=ALWAYS, init-value=0}, required-interface=IfVeSMSbThdRwLtStFrwdSwReqV
      IfVeSMSbThdRwRtStBkReclnDnwdSwReq: nonqueued-receiver-com-spec{data-element=IfVeSMSbThdRwRtStBkReclnDnwdSwReq/Val, filter=data-filter-type=ALWAYS, init-value=0}, required-interface=IfVeSMSbThdRwRtStBkReclnDnwdSwReq
      IfVeSMSbThdRwRtStBkReclnDnwdSwReqV: nonqueued-receiver-com-spec{data-element=IfVeSMSbThdRwRtStBkReclnDnwdSwReqV/Val, filter=data-filter-type=ALWAYS, init-value=0}, required-interface=IfVeSMSbThdRwRtStBkReclnDnwdSwReqV
      IfVeSMSbThdRwRtStBkReclnUpwdSwReq: nonqueued-receiver-com-spec{data-element=IfVeSMSbThdRwRtStBkReclnUpwdSwReq/Val, filter=data-filter-type=ALWAYS, init-value=0}, required-interface=IfVeSMSbThdRwRtStBkReclnUpwdSwReq
      IfVeSMSbThdRwRtStBkReclnUpwdSwReqV: nonqueued-receiver-com-spec{data-element=IfVeSMSbThdRwRtStBkReclnUpwdSwReqV/Val, filter=data-filter-type=ALWAYS, init-value=0}, required-interface=IfVeSMSbThdRwRtStBkReclnUpwdSwReqV
      IfVeSMSbThdRwRtStBkwdSwReq: nonqueued-receiver-com-spec{data-element=IfVeSMSbThdRwRtStBkwdSwReq/Val, filter=data-filter-type=ALWAYS, init-value=0}, required-interface=IfVeSMSbThdRwRtStBkwdSwReq
      IfVeSMSbThdRwRtStBkwdSwReqV: nonqueued-receiver-com-spec{data-element=IfVeSMSbThdRwRtStBkwdSwReqV/Val, filter=data-filter-type=ALWAYS, init-value=0}, required-interface=IfVeSMSbThdRwRtStBkwdSwReqV
      IfVeSMSbThdRwRtStFrwdSwReq: nonqueued-receiver-com-spec{data-element=IfVeSMSbThdRwRtStFrwdSwReq/Val, filter=data-filter-type=ALWAYS, init-value=0}, required-interface=IfVeSMSbThdRwRtStFrwdSwReq
      IfVeSMSbThdRwRtStFrwdSwReqV: nonqueued-receiver-com-spec{data-element=IfVeSMSbThdRwRtStFrwdSwReqV/Val, filter=data-filter-type=ALWAYS, init-value=0}, required-interface=IfVeSMSbThdRwRtStFrwdSwReqV
      IfVeSMSeSecLTMemHMI2LReq1: nonqueued-receiver-com-spec{data-element=IfVeSMSeSecLTMemHMI2LReq1/Val, filter=data-filter-type=ALWAYS, init-value=ComSpec123bd393_01b7339728256b88:0}, required-interface=IfVeSMSeSecLTMemHMI2LReq1
      IfVeSMSeSecLTMemHMI2RReq1: nonqueued-receiver-com-spec{data-element=IfVeSMSeSecLTMemHMI2RReq1/Val, filter=data-filter-type=ALWAYS, init-value=ComSpecc98d9a2e_ac9a9b23856a7b71:0}, required-interface=IfVeSMSeSecLTMemHMI2RReq1
      IfVeSMSuRrLtStFtUpwdPstnHMI2LReq: nonqueued-receiver-com-spec{data-element=TrgtPos/Val, filter=data-filter-type=ALWAYS, init-value=ComSpec594183e5_fd0d0d27cbe215c1:4095}, required-interface=TrgtPos
      IfVeSMSuRrLtStFtUpwdPstnHMI2LReqV: nonqueued-receiver-com-spec{data-element=SeatPosV/Val, filter=data-filter-type=ALWAYS, init-value=1}, required-interface=SeatPosV
      IfVeSMSuRrRtStFtUpwdPstnHMI2RReq: nonqueued-receiver-com-spec{data-element=TrgtPos/Val, filter=data-filter-type=ALWAYS, init-value=ComSpeca43937f9_972df7964322b013:4095}, required-interface=TrgtPos
      IfVeSMSuRrRtStFtUpwdPstnHMI2RReqV: nonqueued-receiver-com-spec{data-element=SeatPosV/Val, filter=data-filter-type=ALWAYS, init-value=ComSpec5da43c10_de09f6297954859e:1}, required-interface=SeatPosV
      IfVeSMSuSeatPosEnable: nonqueued-receiver-com-spec{data-element=IfVeSMSuSeatPosEnable/Val, filter=data-filter-type=ALWAYS, init-value=ComSpec7d4e6b00_5183999af753ae45:0}, required-interface=IfVeSMSuSeatPosEnable
      PassStPosRclRspStat: nonqueued-receiver-com-spec{data-element=PosRclRspStat/Val, filter=data-filter-type=ALWAYS, init-value=0}, required-interface=PosRclRspStat
      SecRwRtStBkReclnDnwdMovBossSwReq: nonqueued-receiver-com-spec{data-element=SecRwRtStBkReclnDnwdMovBossSwReq/Val, filter=data-filter-type=ALWAYS, init-value=0}, required-interface=SecRwRtStBkReclnDnwdMovBossSwReq
      SecRwRtStBkReclnDnwdMovBossSwReqV: nonqueued-receiver-com-spec{data-element=SecRwRtStBkReclnDnwdMovBossSwReqV/Val, filter=data-filter-type=ALWAYS, init-value=0}, required-interface=SecRwRtStBkReclnDnwdMovBossSwReqV
      SecRwRtStBkReclnUpwdMovBossSwReq: nonqueued-receiver-com-spec{data-element=SecRwRtStBkReclnUpwdMovBossSwReq/Val, filter=data-filter-type=ALWAYS, init-value=0}, required-interface=SecRwRtStBkReclnUpwdMovBossSwReq
      SecRwRtStBkReclnUpwdMovBossSwReqV: nonqueued-receiver-com-spec{data-element=SecRwRtStBkReclnUpwdMovBossSwReqV/Val, filter=data-filter-type=ALWAYS, init-value=0}, required-interface=SecRwRtStBkReclnUpwdMovBossSwReqV
      SecRwRtStBkwdMovBossSwReq: nonqueued-receiver-com-spec{data-element=SecRwRtStBkwdMovBossSwReq/Val, filter=data-filter-type=ALWAYS, init-value=0}, required-interface=SecRwRtStBkwdMovBossSwReq
      SecRwRtStBkwdMovBossSwReqV: nonqueued-receiver-com-spec{data-element=SecRwRtStBkwdMovBossSwReqV/Val, filter=data-filter-type=ALWAYS, init-value=0}, required-interface=SecRwRtStBkwdMovBossSwReqV
      SecRwRtStFrwdMovBossSwReq: nonqueued-receiver-com-spec{data-element=SecRwRtStFrwdMovBossSwReq/Val, filter=data-filter-type=ALWAYS, init-value=0}, required-interface=SecRwRtStFrwdMovBossSwReq
      SecRwRtStFrwdMovBossSwReqV: nonqueued-receiver-com-spec{data-element=SecRwRtStFrwdMovBossSwReqV/Val, filter=data-filter-type=ALWAYS, init-value=0}, required-interface=SecRwRtStFrwdMovBossSwReqV
      StSlctSwReq: nonqueued-receiver-com-spec{data-element=LugMdSelectSwt/Val, filter=data-filter-type=ALWAYS, init-value=ComSpec0326beac_7aee0a50bbb6120c:0}, required-interface=LugMdSelectSwt
      StSlctSwReqV: nonqueued-receiver-com-spec{data-element=Validity/Val, filter=data-filter-type=ALWAYS, init-value=0}, required-interface=Validity
    behavior SeatMdSwtchArbt_InternalBehavior
      timing event TMT_SeatMdSwtchArbtRunnable: start-on-event=SeatMdSwtchArbtRunnable, period=0.01
      port-api-options:
        enable-take-address=false, indirect-api=false, port=IfDrvSeatMemSwtAct1
        enable-take-address=false, indirect-api=false, port=IfDrvSeatMemSwtActV1
        enable-take-address=false, indirect-api=false, port=IfVeSMSb_DrvStCshnRrDnwdMovSwAct
        enable-take-address=false, indirect-api=false, port=IfVeSMSb_DrvStCshnRrDnwdMovSwActV
        enable-take-address=false, indirect-api=false, port=IfVeSMSbBosSWBkwdHMI2RReq
        enable-take-address=false, indirect-api=false, port=IfVeSMSbBosSWFrwdHMI2RReq
        enable-take-address=false, indirect-api=false, port=IfVeSMSbBosSWStBkReclnDnwdHMI2RReq
        enable-take-address=false, indirect-api=false, port=IfVeSMSbBosSWStBkReclnUpwdHMI2RReq
        enable-take-address=false, indirect-api=false, port=IfVeSMSbDrvStBkReclnDnwdMovSwAct
        enable-take-address=false, indirect-api=false, port=IfVeSMSbDrvStBkReclnDnwdMovSwActV
        enable-take-address=false, indirect-api=false, port=IfVeSMSbDrvStBkReclnUpwdMovSwAct
        enable-take-address=false, indirect-api=false, port=IfVeSMSbDrvStBkReclnUpwdMovSwActV
        enable-take-address=false, indirect-api=false, port=IfVeSMSbDrvStBkwdMovSwAct
        enable-take-address=false, indirect-api=false, port=IfVeSMSbDrvStBkwdMovSwActV
        enable-take-address=false, indirect-api=false, port=IfVeSMSbDrvStCshnFrntDnwdMovSwAct
        enable-take-address=false, indirect-api=false, port=IfVeSMSbDrvStCshnFrntDnwdMovSwActV
        enable-take-address=false, indirect-api=false, port=IfVeSMSbDrvStCshnFrntUpwdMovSwAct
        enable-take-address=false, indirect-api=false, port=IfVeSMSbDrvStCshnFrntUpwdMovSwActV
        enable-take-address=false, indirect-api=false, port=IfVeSMSbDrvStCshnRrUpwdMovSwAct
        enable-take-address=false, indirect-api=false, port=IfVeSMSbDrvStCshnRrUpwdMovSwActV
        enable-take-address=false, indirect-api=false, port=IfVeSMSbDrvStFrwdMovSwAct
        enable-take-address=false, indirect-api=false, port=IfVeSMSbDrvStFrwdMovSwActV
        enable-take-address=false, indirect-api=false, port=IfVeSMSbPassStBkReclnDnwdMovSwAct
        enable-take-address=false, indirect-api=false, port=IfVeSMSbPassStBkReclnDnwdMovSwActV
        enable-take-address=false, indirect-api=false, port=IfVeSMSbPassStBkReclnUpwdMovSwAct
        enable-take-address=false, indirect-api=false, port=IfVeSMSbPassStBkReclnUpwdMovSwActV
        enable-take-address=false, indirect-api=false, port=IfVeSMSbPassStBkwdMovSwAct
        enable-take-address=false, indirect-api=false, port=IfVeSMSbPassStBkwdMovSwActV
        enable-take-address=false, indirect-api=false, port=IfVeSMSbPassStCshnFrntDnwdMovSwAct
        enable-take-address=false, indirect-api=false, port=IfVeSMSbPassStCshnFrntDnwdMovSwActV
        enable-take-address=false, indirect-api=false, port=IfVeSMSbPassStCshnFrntUpwdMovSwAct
        enable-take-address=false, indirect-api=false, port=IfVeSMSbPassStCshnFrntUpwdMovSwActV
        enable-take-address=false, indirect-api=false, port=IfVeSMSbPassStCshnRrDnwdMovSwAct
        enable-take-address=false, indirect-api=false, port=IfVeSMSbPassStCshnRrDnwdMovSwActV
        enable-take-address=false, indirect-api=false, port=IfVeSMSbPassStCshnRrUpwdMovSwAct
        enable-take-address=false, indirect-api=false, port=IfVeSMSbPassStCshnRrUpwdMovSwActV
        enable-take-address=false, indirect-api=false, port=IfVeSMSbPassStFrwdMovSwAct
        enable-take-address=false, indirect-api=false, port=IfVeSMSbPassStFrwdMovSwActV
        enable-take-address=false, indirect-api=false, port=IfVeSMSbSecRwLtStArmScrnHMI2LReq
        enable-take-address=false, indirect-api=false, port=IfVeSMSbSecRwLtStFtDnwdHMI2LReq
        enable-take-address=false, indirect-api=false, port=IfVeSMSbSecRwLtStFtUpwdHMI2LReq
        enable-take-address=false, indirect-api=false, port=IfVeSMSbSecRwLtStLcMovActv
        enable-take-address=false, indirect-api=false, port=IfVeSMSbSecRwRtStArmScrnHMI2RReq
        enable-take-address=false, indirect-api=false, port=IfVeSMSbSecRwRtStBkReclnDnwdHMI2RReq
        enable-take-address=false, indirect-api=false, port=IfVeSMSbSecRwRtStBkReclnDnwdSwReq
        enable-take-address=false, indirect-api=false, port=IfVeSMSbSecRwRtStBkReclnDnwdSwReqV
        enable-take-address=false, indirect-api=false, port=IfVeSMSbSecRwRtStBkReclnUpwdHMI2RReq
        enable-take-address=false, indirect-api=false, port=IfVeSMSbSecRwRtStBkReclnUpwdSwReq
        enable-take-address=false, indirect-api=false, port=IfVeSMSbSecRwRtStBkReclnUpwdSwReqV
        enable-take-address=false, indirect-api=false, port=IfVeSMSbSecRwRtStBkwdHMI2RReq
        enable-take-address=false, indirect-api=false, port=IfVeSMSbSecRwRtStBkwdSwReq
        enable-take-address=false, indirect-api=false, port=IfVeSMSbSecRwRtStBkwdSwReqV
        enable-take-address=false, indirect-api=false, port=IfVeSMSbSecRwRtStFrwdHMI2RReq
        enable-take-address=false, indirect-api=false, port=IfVeSMSbSecRwRtStFrwdSwReq
        enable-take-address=false, indirect-api=false, port=IfVeSMSbSecRwRtStFrwdSwReqV
        enable-take-address=false, indirect-api=false, port=IfVeSMSbSecRwRtStFtDnwdHMI2RReq
        enable-take-address=false, indirect-api=false, port=IfVeSMSbSecRwRtStFtUpwdHMI2RReq
        enable-take-address=false, indirect-api=false, port=IfVeSMSbSecRwRtStHdrstDnwdHMI2RReq
        enable-take-address=false, indirect-api=false, port=IfVeSMSbSecRwRtStHdrstUpwdHMI2RReq
        enable-take-address=false, indirect-api=false, port=IfVeSMSbSecRwRtStLgrstDnwdHMI2RReq
        enable-take-address=false, indirect-api=false, port=IfVeSMSbSecRwRtStLgrstDnwdSwReq
        enable-take-address=false, indirect-api=false, port=IfVeSMSbSecRwRtStLgrstDnwdSwReqV
        enable-take-address=false, indirect-api=false, port=IfVeSMSbSecRwRtStLgrstUpwdHMI2RReq
        enable-take-address=false, indirect-api=false, port=IfVeSMSbSecRwRtStLgrstUpwdSwReq
        enable-take-address=false, indirect-api=false, port=IfVeSMSbSecRwRtStLgrstUpwdSwReqV
        enable-take-address=false, indirect-api=false, port=IfVeSMSbSecRwRtStLmbrHMI2RReq
        enable-take-address=false, indirect-api=false, port=IfVeSMSbSecRwRtStLtwdHMI2RReq
        enable-take-address=false, indirect-api=false, port=IfVeSMSbSecRwRtStRtwdHMI2RReq
        enable-take-address=false, indirect-api=false, port=IfVeSMSbThdRwLtStBkReclnDnwdSwReq
        enable-take-address=false, indirect-api=false, port=IfVeSMSbThdRwLtStBkReclnDnwdSwReqV
        enable-take-address=false, indirect-api=false, port=IfVeSMSbThdRwLtStBkReclnUpwdSwReq
        enable-take-address=false, indirect-api=false, port=IfVeSMSbThdRwLtStBkReclnUpwdSwReqV
        enable-take-address=false, indirect-api=false, port=IfVeSMSbThdRwLtStBkwdSwReq
        enable-take-address=false, indirect-api=false, port=IfVeSMSbThdRwLtStBkwdSwReqV
        enable-take-address=false, indirect-api=false, port=IfVeSMSbThdRwLtStFrwdSwReq
        enable-take-address=false, indirect-api=false, port=IfVeSMSbThdRwLtStFrwdSwReqV
        enable-take-address=false, indirect-api=false, port=IfVeSMSbThdRwRtStBkReclnDnwdSwReq
        enable-take-address=false, indirect-api=false, port=IfVeSMSbThdRwRtStBkReclnDnwdSwReqV
        enable-take-address=false, indirect-api=false, port=IfVeSMSbThdRwRtStBkReclnUpwdSwReq
        enable-take-address=false, indirect-api=false, port=IfVeSMSbThdRwRtStBkReclnUpwdSwReqV
        enable-take-address=false, indirect-api=false, port=IfVeSMSbThdRwRtStBkwdSwReq
        enable-take-address=false, indirect-api=false, port=IfVeSMSbThdRwRtStBkwdSwReqV
        enable-take-address=false, indirect-api=false, port=IfVeSMSbThdRwRtStFrwdSwReq
        enable-take-address=false, indirect-api=false, port=IfVeSMSbThdRwRtStFrwdSwReqV
        enable-take-address=false, indirect-api=false, port=IfVeSMSeSecLTMemHMI2LReq1
        enable-take-address=false, indirect-api=false, port=IfVeSMSeSecLTMemHMI2RReq1
      runnable SeatMdSwtchArbtRunnable
        data-receive-point-by-arguments:
          178 x access:
            REC_IfDrvSeatMemSwtAct1_Val: accessed-variable=IfDrvSeatMemSwtAct1.Val
            REC_IfDrvSeatMemSwtActV1_Val: accessed-variable=IfDrvSeatMemSwtActV1.Val
            REC_IfSecRwLtStCushnFrtDnwdHMI2LReq_Val: accessed-variable=IfSecRwLtStCushnFrtDnwdHMI2LReq.Val
            REC_IfSecRwLtStCushnFrtUpwdDnwdMovmtVirtCtrlReq_Val: accessed-variable=IfSecRwLtStCushnFrtUpwdDnwdMovmtVirtCtrlReq.Val
            REC_IfSecRwLtStCushnFrtUpwdHMI2LReq_Val: accessed-variable=IfSecRwLtStCushnFrtUpwdHMI2LReq.Val
            REC_IfSecRwLtStFwdBkwdMovmtVirtCtrlReq_Val: accessed-variable=IfSecRwLtStFwdBkwdMovmtVirtCtrlReq.Val
            REC_IfSecRwLtStLgrstOtwdInwdMovmtVirtCtrlReq_Val: accessed-variable=IfSecRwLtStLgrstOtwdInwdMovmtVirtCtrlReq.Val
            REC_IfSecRwLtStLgrstUpwdDnwdMovmtVirtCtrlReq_Val: accessed-variable=IfSecRwLtStLgrstUpwdDnwdMovmtVirtCtrlReq.Val
            REC_IfSecRwLtStRclUpwdDnwdMovmtVirtCtrlReq_Val: accessed-variable=IfSecRwLtStRclUpwdDnwdMovmtVirtCtrlReq.Val
            REC_IfSecRwRtStCushnFrtDnwdHMI2LReq_Val: accessed-variable=IfSecRwRtStCushnFrtDnwdHMI2LReq.Val
            REC_IfSecRwRtStCushnFrtUpwdDnwdMovmtVirtCtrlReq_Val: accessed-variable=IfSecRwRtStCushnFrtUpwdDnwdMovmtVirtCtrlReq.Val
            REC_IfSecRwRtStCushnFrtUpwdHMI2LReq_Val: accessed-variable=IfSecRwRtStCushnFrtUpwdHMI2LReq.Val
            REC_IfSecRwRtStFwdBkwdMovmtVirtCtrlReq_Val: accessed-variable=IfSecRwRtStFwdBkwdMovmtVirtCtrlReq.Val
            REC_IfSecRwRtStLgrstInwdSwReq_Val: accessed-variable=IfSecRwRtStLgrstInwdSwReq.Val
            REC_IfSecRwRtStLgrstInwdSwReqV_Val: accessed-variable=IfSecRwRtStLgrstInwdSwReqV.Val
            REC_IfSecRwRtStLgrstOtwdInwdMovmtVirtCtrlReq_Val: accessed-variable=IfSecRwRtStLgrstOtwdInwdMovmtVirtCtrlReq.Val
            REC_IfSecRwRtStLgrstOtwdSwReq_Val: accessed-variable=IfSecRwRtStLgrstOtwdSwReq.Val
            REC_IfSecRwRtStLgrstOtwdSwReqV_Val: accessed-variable=IfSecRwRtStLgrstOtwdSwReqV.Val
            REC_IfSecRwRtStLgrstUpwdDnwdMovmtVirtCtrlReq_Val: accessed-variable=IfSecRwRtStLgrstUpwdDnwdMovmtVirtCtrlReq.Val
            REC_IfSecRwRtStRclUpwdDnwdMovmtVirtCtrlReq_Val: accessed-variable=IfSecRwRtStRclUpwdDnwdMovmtVirtCtrlReq.Val
            REC_IfSecRwRtStZeroGrvyDnwdSwReq_Val: accessed-variable=IfSecRwRtStZeroGrvyDnwdSwReq.Val
            REC_IfSecRwRtStZeroGrvyDnwdSwReqV_Val: accessed-variable=IfSecRwRtStZeroGrvyDnwdSwReqV.Val
            REC_IfSecRwRtStZeroGrvyUpwdSwReq_Val: accessed-variable=IfSecRwRtStZeroGrvyUpwdSwReq.Val
            REC_IfSecRwRtStZeroGrvyUpwdSwReqV_Val: accessed-variable=IfSecRwRtStZeroGrvyUpwdSwReqV.Val
            REC_IfVeSMSb_DrvStCshnRrDnwdMovSwAct_Val: accessed-variable=IfVeSMSb_DrvStCshnRrDnwdMovSwAct.Val
            REC_IfVeSMSb_DrvStCshnRrDnwdMovSwActV_Val: accessed-variable=IfVeSMSb_DrvStCshnRrDnwdMovSwActV.Val
            REC_IfVeSMSb2LBkReclnSwReq_Val: accessed-variable=IfVeSMSb2LBkReclnSwReq.Val
            REC_IfVeSMSb2LBkReclnSwReqV_Val: accessed-variable=IfVeSMSb2LBkReclnSwReqV.Val
            REC_IfVeSMSb2LSecRwStBkReclnDnwdSwActv_Val: accessed-variable=IfVeSMSb2LSecRwStBkReclnDnwdSwActv.Val
            REC_IfVeSMSb2LSecRwStBkReclnUpwdSwActv_Val: accessed-variable=IfVeSMSb2LSecRwStBkReclnUpwdSwActv.Val
            REC_IfVeSMSb2LSecRwStBkwdSwActv_Val: accessed-variable=IfVeSMSb2LSecRwStBkwdSwActv.Val
            REC_IfVeSMSb2LSecRwStFrwdSwActv_Val: accessed-variable=IfVeSMSb2LSecRwStFrwdSwActv.Val
            REC_IfVeSMSb2LSecRwStLgrstDnwdSwActv_Val: accessed-variable=IfVeSMSb2LSecRwStLgrstDnwdSwActv.Val
            REC_IfVeSMSb2LSecRwStLgrstUpwdSwActv_Val: accessed-variable=IfVeSMSb2LSecRwStLgrstUpwdSwActv.Val
            REC_IfVeSMSbBosSWBkwdHMI2RReq_Val: accessed-variable=IfVeSMSbBosSWBkwdHMI2RReq.Val
            REC_IfVeSMSbBosSWFrwdHMI2RReq_Val: accessed-variable=IfVeSMSbBosSWFrwdHMI2RReq.Val
            REC_IfVeSMSbBosSWStBkReclnDnwdHMI2RReq_Val: accessed-variable=IfVeSMSbBosSWStBkReclnDnwdHMI2RReq.Val
            REC_IfVeSMSbBosSWStBkReclnUpwdHMI2RReq_Val: accessed-variable=IfVeSMSbBosSWStBkReclnUpwdHMI2RReq.Val
            REC_IfVeSMSbDrvStBkReclnDnwdMovSwAct_Val: accessed-variable=IfVeSMSbDrvStBkReclnDnwdMovSwAct.Val
            REC_IfVeSMSbDrvStBkReclnDnwdMovSwActV_Val: accessed-variable=IfVeSMSbDrvStBkReclnDnwdMovSwActV.Val
            REC_IfVeSMSbDrvStBkReclnUpwdMovSwAct_Val: accessed-variable=IfVeSMSbDrvStBkReclnUpwdMovSwAct.Val
            REC_IfVeSMSbDrvStBkReclnUpwdMovSwActV_Val: accessed-variable=IfVeSMSbDrvStBkReclnUpwdMovSwActV.Val
            REC_IfVeSMSbDrvStBkwdMovSwAct_Val: accessed-variable=IfVeSMSbDrvStBkwdMovSwAct.Val
            REC_IfVeSMSbDrvStBkwdMovSwActV_Val: accessed-variable=IfVeSMSbDrvStBkwdMovSwActV.Val
            REC_IfVeSMSbDrvStCshnFrntDnwdMovSwAct_Val: accessed-variable=IfVeSMSbDrvStCshnFrntDnwdMovSwAct.Val
            REC_IfVeSMSbDrvStCshnFrntDnwdMovSwActV_Val: accessed-variable=IfVeSMSbDrvStCshnFrntDnwdMovSwActV.Val
            REC_IfVeSMSbDrvStCshnFrntUpwdMovSwAct_Val: accessed-variable=IfVeSMSbDrvStCshnFrntUpwdMovSwAct.Val
            REC_IfVeSMSbDrvStCshnFrntUpwdMovSwActV_Val: accessed-variable=IfVeSMSbDrvStCshnFrntUpwdMovSwActV.Val
            REC_IfVeSMSbDrvStCshnRrUpwdMovSwAct_Val: accessed-variable=IfVeSMSbDrvStCshnRrUpwdMovSwAct.Val
            REC_IfVeSMSbDrvStCshnRrUpwdMovSwActV_Val: accessed-variable=IfVeSMSbDrvStCshnRrUpwdMovSwActV.Val
            REC_IfVeSMSbDrvStFrwdMovSwAct_Val: accessed-variable=IfVeSMSbDrvStFrwdMovSwAct.Val
            REC_IfVeSMSbDrvStFrwdMovSwActV_Val: accessed-variable=IfVeSMSbDrvStFrwdMovSwActV.Val
            REC_IfVeSMSbPassStBkReclnDnwdMovBosSwAct_Val: accessed-variable=IfVeSMSbPassStBkReclnDnwdMovBosSwAct.Val
            REC_IfVeSMSbPassStBkReclnDnwdMovBosSwActV_Val: accessed-variable=IfVeSMSbPassStBkReclnDnwdMovBosSwActV.Val
            REC_IfVeSMSbPassStBkReclnDnwdMovSwAct_Val: accessed-variable=IfVeSMSbPassStBkReclnDnwdMovSwAct.Val
            REC_IfVeSMSbPassStBkReclnDnwdMovSwActV_Val: accessed-variable=IfVeSMSbPassStBkReclnDnwdMovSwActV.Val
            REC_IfVeSMSbPassStBkReclnUpwdMovBosSwAct_Val: accessed-variable=IfVeSMSbPassStBkReclnUpwdMovBosSwAct.Val
            REC_IfVeSMSbPassStBkReclnUpwdMovBosSwActV_Val: accessed-variable=IfVeSMSbPassStBkReclnUpwdMovBosSwActV.Val
            REC_IfVeSMSbPassStBkReclnUpwdMovSwAct_Val: accessed-variable=IfVeSMSbPassStBkReclnUpwdMovSwAct.Val
            REC_IfVeSMSbPassStBkReclnUpwdMovSwActV_Val: accessed-variable=IfVeSMSbPassStBkReclnUpwdMovSwActV.Val
            REC_IfVeSMSbPassStBkwdMovBosSwAct_Val: accessed-variable=IfVeSMSbPassStBkwdMovBosSwAct.Val
            REC_IfVeSMSbPassStBkwdMovBosSwActV_Val: accessed-variable=IfVeSMSbPassStBkwdMovBosSwActV.Val
            REC_IfVeSMSbPassStBkwdMovSwAct_Val: accessed-variable=IfVeSMSbPassStBkwdMovSwAct.Val
            REC_IfVeSMSbPassStBkwdMovSwActV_Val: accessed-variable=IfVeSMSbPassStBkwdMovSwActV.Val
            REC_IfVeSMSbPassStCshnFrntDnwdMovSwAct_Val: accessed-variable=IfVeSMSbPassStCshnFrntDnwdMovSwAct.Val
            REC_IfVeSMSbPassStCshnFrntDnwdMovSwActV_Val: accessed-variable=IfVeSMSbPassStCshnFrntDnwdMovSwActV.Val
            REC_IfVeSMSbPassStCshnFrntUpwdMovSwAct_Val: accessed-variable=IfVeSMSbPassStCshnFrntUpwdMovSwAct.Val
            REC_IfVeSMSbPassStCshnFrntUpwdMovSwActV_Val: accessed-variable=IfVeSMSbPassStCshnFrntUpwdMovSwActV.Val
            REC_IfVeSMSbPassStCshnRrDnwdMovSwAct_Val: accessed-variable=IfVeSMSbPassStCshnRrDnwdMovSwAct.Val
            REC_IfVeSMSbPassStCshnRrDnwdMovSwActV_Val: accessed-variable=IfVeSMSbPassStCshnRrDnwdMovSwActV.Val
            REC_IfVeSMSbPassStCshnRrUpwdMovSwAct_Val: accessed-variable=IfVeSMSbPassStCshnRrUpwdMovSwAct.Val
            REC_IfVeSMSbPassStCshnRrUpwdMovSwActV_Val: accessed-variable=IfVeSMSbPassStCshnRrUpwdMovSwActV.Val
            REC_IfVeSMSbPassStFrwdMovBosSwAct_Val: accessed-variable=IfVeSMSbPassStFrwdMovBosSwAct.Val
            REC_IfVeSMSbPassStFrwdMovBosSwActV_Val: accessed-variable=IfVeSMSbPassStFrwdMovBosSwActV.Val
            REC_IfVeSMSbPassStFrwdMovSwAct_Val: accessed-variable=IfVeSMSbPassStFrwdMovSwAct.Val
            REC_IfVeSMSbPassStFrwdMovSwActV_Val: accessed-variable=IfVeSMSbPassStFrwdMovSwActV.Val
            REC_IfVeSMSbRrLtStFtDnwdHMI2LReq_Val: accessed-variable=IfVeSMSbRrLtStFtDnwdHMI2LReq.Val
            REC_IfVeSMSbRrLtStFtUpwdHMI2LReq_Val: accessed-variable=IfVeSMSbRrLtStFtUpwdHMI2LReq.Val
            REC_IfVeSMSbRrPsgComprtStBkReclnDnwdSwReq_Val: accessed-variable=IfVeSMSbRrPsgComprtStBkReclnDnwdSwReq.Val
            REC_IfVeSMSbRrPsgComprtStBkReclnDnwdSwReqV_Val: accessed-variable=IfVeSMSbRrPsgComprtStBkReclnDnwdSwReqV.Val
            REC_IfVeSMSbRrPsgComprtStBkReclnUpwdSwReq_Val: accessed-variable=IfVeSMSbRrPsgComprtStBkReclnUpwdSwReq.Val
            REC_IfVeSMSbRrPsgComprtStBkReclnUpwdSwReqV_Val: accessed-variable=IfVeSMSbRrPsgComprtStBkReclnUpwdSwReqV.Val
            REC_IfVeSMSbRrPsgComprtStBkwdSwReq_Val: accessed-variable=IfVeSMSbRrPsgComprtStBkwdSwReq.Val
            REC_IfVeSMSbRrPsgComprtStBkwdSwReqV_Val: accessed-variable=IfVeSMSbRrPsgComprtStBkwdSwReqV.Val
            REC_IfVeSMSbRrPsgComprtStFrwdSwReq_Val: accessed-variable=IfVeSMSbRrPsgComprtStFrwdSwReq.Val
            REC_IfVeSMSbRrPsgComprtStFrwdSwReqV_Val: accessed-variable=IfVeSMSbRrPsgComprtStFrwdSwReqV.Val
            REC_IfVeSMSbRrRtStFtDnwdHMI2RReq_Val: accessed-variable=IfVeSMSbRrRtStFtDnwdHMI2RReq.Val
            REC_IfVeSMSbRrRtStFtUpwdHMI2RReq_Val: accessed-variable=IfVeSMSbRrRtStFtUpwdHMI2RReq.Val
            REC_IfVeSMSbSecRwLtStArmScrnHMI2LReq_Val: accessed-variable=IfVeSMSbSecRwLtStArmScrnHMI2LReq.Val
            REC_IfVeSMSbSecRwLtStBkReclnDnwdHMI2LReq_Val: accessed-variable=IfVeSMSbSecRwLtStBkReclnDnwdHMI2LReq.Val
            REC_IfVeSMSbSecRwLtStBkReclnUpwdHMI2LReq_Val: accessed-variable=IfVeSMSbSecRwLtStBkReclnUpwdHMI2LReq.Val
            REC_IfVeSMSbSecRwLtStBkwdHMI2LReq_Val: accessed-variable=IfVeSMSbSecRwLtStBkwdHMI2LReq.Val
            REC_IfVeSMSbSecRwLtStFrwdHMI2LReq_Val: accessed-variable=IfVeSMSbSecRwLtStFrwdHMI2LReq.Val
            REC_IfVeSMSbSecRwLtStFtClsHMI2LReq_Val: accessed-variable=IfVeSMSbSecRwLtStFtClsHMI2LReq.Val
            REC_IfVeSMSbSecRwLtStFtDnwdHMI2LReq_Val: accessed-variable=IfVeSMSbSecRwLtStFtDnwdHMI2LReq.Val
            REC_IfVeSMSbSecRwLtStFtOpenHMI2LReq_Val: accessed-variable=IfVeSMSbSecRwLtStFtOpenHMI2LReq.Val
            REC_IfVeSMSbSecRwLtStFtUpwdHMI2LReq_Val: accessed-variable=IfVeSMSbSecRwLtStFtUpwdHMI2LReq.Val
            REC_IfVeSMSbSecRwLtStHdrstBkwdHMI2LReq_Val: accessed-variable=IfVeSMSbSecRwLtStHdrstBkwdHMI2LReq.Val
            REC_IfVeSMSbSecRwLtStHdrstDnwdHMI2LReq_Val: accessed-variable=IfVeSMSbSecRwLtStHdrstDnwdHMI2LReq.Val
            REC_IfVeSMSbSecRwLtStHdrstFrwdHMI2LReq_Val: accessed-variable=IfVeSMSbSecRwLtStHdrstFrwdHMI2LReq.Val
            REC_IfVeSMSbSecRwLtStHdrstUpwdHMI2LReq_Val: accessed-variable=IfVeSMSbSecRwLtStHdrstUpwdHMI2LReq.Val
            REC_IfVeSMSbSecRwLtStLcMovActv_Val: accessed-variable=IfVeSMSbSecRwLtStLcMovActv.Val
            REC_IfVeSMSbSecRwLtStLgrstDnwdHMI2LReq_Val: accessed-variable=IfVeSMSbSecRwLtStLgrstDnwdHMI2LReq.Val
            REC_IfVeSMSbSecRwLtStLgrstInwdHMI2LReq_Val: accessed-variable=IfVeSMSbSecRwLtStLgrstInwdHMI2LReq.Val
            REC_IfVeSMSbSecRwLtStLgrstOtwdHMI2LReq_Val: accessed-variable=IfVeSMSbSecRwLtStLgrstOtwdHMI2LReq.Val
            REC_IfVeSMSbSecRwLtStLgrstUpwdHMI2LReq_Val: accessed-variable=IfVeSMSbSecRwLtStLgrstUpwdHMI2LReq.Val
            REC_IfVeSMSbSecRwLtStLtwdHMI2LReq_Val: accessed-variable=IfVeSMSbSecRwLtStLtwdHMI2LReq.Val
            REC_IfVeSMSbSecRwLtStRtwdHMI2LReq_Val: accessed-variable=IfVeSMSbSecRwLtStRtwdHMI2LReq.Val
            REC_IfVeSMSbSecRwRtStArmScrnHMI2RReq_Val: accessed-variable=IfVeSMSbSecRwRtStArmScrnHMI2RReq.Val
            REC_IfVeSMSbSecRwRtStBkReclnDnwdHMI2RReq_Val: accessed-variable=IfVeSMSbSecRwRtStBkReclnDnwdHMI2RReq.Val
            REC_IfVeSMSbSecRwRtStBkReclnDnwdSwReq_Val: accessed-variable=IfVeSMSbSecRwRtStBkReclnDnwdSwReq.Val
            REC_IfVeSMSbSecRwRtStBkReclnDnwdSwReqV_Val: accessed-variable=IfVeSMSbSecRwRtStBkReclnDnwdSwReqV.Val
            REC_IfVeSMSbSecRwRtStBkReclnUpwdHMI2RReq_Val: accessed-variable=IfVeSMSbSecRwRtStBkReclnUpwdHMI2RReq.Val
            REC_IfVeSMSbSecRwRtStBkReclnUpwdSwReq_Val: accessed-variable=IfVeSMSbSecRwRtStBkReclnUpwdSwReq.Val
            REC_IfVeSMSbSecRwRtStBkReclnUpwdSwReqV_Val: accessed-variable=IfVeSMSbSecRwRtStBkReclnUpwdSwReqV.Val
            REC_IfVeSMSbSecRwRtStBkwdHMI2RReq_Val: accessed-variable=IfVeSMSbSecRwRtStBkwdHMI2RReq.Val
            REC_IfVeSMSbSecRwRtStBkwdSwReq_Val: accessed-variable=IfVeSMSbSecRwRtStBkwdSwReq.Val
            REC_IfVeSMSbSecRwRtStBkwdSwReqV_Val: accessed-variable=IfVeSMSbSecRwRtStBkwdSwReqV.Val
            REC_IfVeSMSbSecRwRtStFrwdHMI2RReq_Val: accessed-variable=IfVeSMSbSecRwRtStFrwdHMI2RReq.Val
            REC_IfVeSMSbSecRwRtStFrwdSwReq_Val: accessed-variable=IfVeSMSbSecRwRtStFrwdSwReq.Val
            REC_IfVeSMSbSecRwRtStFrwdSwReqV_Val: accessed-variable=IfVeSMSbSecRwRtStFrwdSwReqV.Val
            REC_IfVeSMSbSecRwRtStFtClsHMI2LReq_Val: accessed-variable=IfVeSMSbSecRwRtStFtClsHMI2LReq.Val
            REC_IfVeSMSbSecRwRtStFtDnwdHMI2RReq_Val: accessed-variable=IfVeSMSbSecRwRtStFtDnwdHMI2RReq.Val
            REC_IfVeSMSbSecRwRtStFtOpenHMI2LReq_Val: accessed-variable=IfVeSMSbSecRwRtStFtOpenHMI2LReq.Val
            REC_IfVeSMSbSecRwRtStFtUpwdHMI2RReq_Val: accessed-variable=IfVeSMSbSecRwRtStFtUpwdHMI2RReq.Val
            REC_IfVeSMSbSecRwRtStHdrstBkwdHMI2RReq_Val: accessed-variable=IfVeSMSbSecRwRtStHdrstBkwdHMI2RReq.Val
            REC_IfVeSMSbSecRwRtStHdrstDnwdHMI2RReq_Val: accessed-variable=IfVeSMSbSecRwRtStHdrstDnwdHMI2RReq.Val
            REC_IfVeSMSbSecRwRtStHdrstFrwdHMI2RReq_Val: accessed-variable=IfVeSMSbSecRwRtStHdrstFrwdHMI2RReq.Val
            REC_IfVeSMSbSecRwRtStHdrstUpwdHMI2RReq_Val: accessed-variable=IfVeSMSbSecRwRtStHdrstUpwdHMI2RReq.Val
            REC_IfVeSMSbSecRwRtStLgrstDnwdHMI2RReq_Val: accessed-variable=IfVeSMSbSecRwRtStLgrstDnwdHMI2RReq.Val
            REC_IfVeSMSbSecRwRtStLgrstDnwdSwReq_Val: accessed-variable=IfVeSMSbSecRwRtStLgrstDnwdSwReq.Val
            REC_IfVeSMSbSecRwRtStLgrstDnwdSwReqV_Val: accessed-variable=IfVeSMSbSecRwRtStLgrstDnwdSwReqV.Val
            REC_IfVeSMSbSecRwRtStLgrstInwdHMI2RReq_Val: accessed-variable=IfVeSMSbSecRwRtStLgrstInwdHMI2RReq.Val
            REC_IfVeSMSbSecRwRtStLgrstOtwdHMI2RReq_Val: accessed-variable=IfVeSMSbSecRwRtStLgrstOtwdHMI2RReq.Val
            REC_IfVeSMSbSecRwRtStLgrstUpwdHMI2RReq_Val: accessed-variable=IfVeSMSbSecRwRtStLgrstUpwdHMI2RReq.Val
            REC_IfVeSMSbSecRwRtStLgrstUpwdSwReq_Val: accessed-variable=IfVeSMSbSecRwRtStLgrstUpwdSwReq.Val
            REC_IfVeSMSbSecRwRtStLgrstUpwdSwReqV_Val: accessed-variable=IfVeSMSbSecRwRtStLgrstUpwdSwReqV.Val
            REC_IfVeSMSbSecRwRtStLmbrHMI2RReq_Val: accessed-variable=IfVeSMSbSecRwRtStLmbrHMI2RReq.Val
            REC_IfVeSMSbSecRwRtStLtwdHMI2RReq_Val: accessed-variable=IfVeSMSbSecRwRtStLtwdHMI2RReq.Val
            REC_IfVeSMSbSecRwRtStRtwdHMI2RReq_Val: accessed-variable=IfVeSMSbSecRwRtStRtwdHMI2RReq.Val
            REC_IfVeSMSbThdRLtStExpdSwReq_Val: accessed-variable=IfVeSMSbThdRLtStExpdSwReq.Val
            REC_IfVeSMSbThdRLtStExpdSwReqV_Val: accessed-variable=IfVeSMSbThdRLtStExpdSwReqV.Val
            REC_IfVeSMSbThdRRtStExpdSwReq_Val: accessed-variable=IfVeSMSbThdRRtStExpdSwReq.Val
            REC_IfVeSMSbThdRRtStExpdSwReqV_Val: accessed-variable=IfVeSMSbThdRRtStExpdSwReqV.Val
            REC_IfVeSMSbThdRwLtStBkReclnDnwdSwReq_Val: accessed-variable=IfVeSMSbThdRwLtStBkReclnDnwdSwReq.Val
            REC_IfVeSMSbThdRwLtStBkReclnDnwdSwReqV_Val: accessed-variable=IfVeSMSbThdRwLtStBkReclnDnwdSwReqV.Val
            REC_IfVeSMSbThdRwLtStBkReclnUpwdSwReq_Val: accessed-variable=IfVeSMSbThdRwLtStBkReclnUpwdSwReq.Val
            REC_IfVeSMSbThdRwLtStBkReclnUpwdSwReqV_Val: accessed-variable=IfVeSMSbThdRwLtStBkReclnUpwdSwReqV.Val
            REC_IfVeSMSbThdRwLtStBkwdSwReq_Val: accessed-variable=IfVeSMSbThdRwLtStBkwdSwReq.Val
            REC_IfVeSMSbThdRwLtStBkwdSwReqV_Val: accessed-variable=IfVeSMSbThdRwLtStBkwdSwReqV.Val
            REC_IfVeSMSbThdRwLtStFrwdSwReq_Val: accessed-variable=IfVeSMSbThdRwLtStFrwdSwReq.Val
            REC_IfVeSMSbThdRwLtStFrwdSwReqV_Val: accessed-variable=IfVeSMSbThdRwLtStFrwdSwReqV.Val
            REC_IfVeSMSbThdRwRtStBkReclnDnwdSwReq_Val: accessed-variable=IfVeSMSbThdRwRtStBkReclnDnwdSwReq.Val
            REC_IfVeSMSbThdRwRtStBkReclnDnwdSwReqV_Val: accessed-variable=IfVeSMSbThdRwRtStBkReclnDnwdSwReqV.Val
            REC_IfVeSMSbThdRwRtStBkReclnUpwdSwReq_Val: accessed-variable=IfVeSMSbThdRwRtStBkReclnUpwdSwReq.Val
            REC_IfVeSMSbThdRwRtStBkReclnUpwdSwReqV_Val: accessed-variable=IfVeSMSbThdRwRtStBkReclnUpwdSwReqV.Val
            REC_IfVeSMSbThdRwRtStBkwdSwReq_Val: accessed-variable=IfVeSMSbThdRwRtStBkwdSwReq.Val
            REC_IfVeSMSbThdRwRtStBkwdSwReqV_Val: accessed-variable=IfVeSMSbThdRwRtStBkwdSwReqV.Val
            REC_IfVeSMSbThdRwRtStFrwdSwReq_Val: accessed-variable=IfVeSMSbThdRwRtStFrwdSwReq.Val
            REC_IfVeSMSbThdRwRtStFrwdSwReqV_Val: accessed-variable=IfVeSMSbThdRwRtStFrwdSwReqV.Val
            REC_IfVeSMSeSecLTMemHMI2LReq1_Val: accessed-variable=IfVeSMSeSecLTMemHMI2LReq1.Val
            REC_IfVeSMSeSecLTMemHMI2RReq1_Val: accessed-variable=IfVeSMSeSecLTMemHMI2RReq1.Val
            REC_IfVeSMSuRrLtStFtUpwdPstnHMI2LReq_Val: accessed-variable=IfVeSMSuRrLtStFtUpwdPstnHMI2LReq.Val
            REC_IfVeSMSuRrLtStFtUpwdPstnHMI2LReqV_Val: accessed-variable=IfVeSMSuRrLtStFtUpwdPstnHMI2LReqV.Val
            REC_IfVeSMSuRrRtStFtUpwdPstnHMI2RReq_Val: accessed-variable=IfVeSMSuRrRtStFtUpwdPstnHMI2RReq.Val
            REC_IfVeSMSuRrRtStFtUpwdPstnHMI2RReqV_Val: accessed-variable=IfVeSMSuRrRtStFtUpwdPstnHMI2RReqV.Val
            REC_IfVeSMSuSeatPosEnable_Val: accessed-variable=IfVeSMSuSeatPosEnable.Val
            REC_PassStPosRclRspStat_Val: accessed-variable=PassStPosRclRspStat.Val
            REC_SecRwRtStBkReclnDnwdMovBossSwReq_Val: accessed-variable=SecRwRtStBkReclnDnwdMovBossSwReq.Val
            REC_SecRwRtStBkReclnDnwdMovBossSwReqV_Val: accessed-variable=SecRwRtStBkReclnDnwdMovBossSwReqV.Val
            REC_SecRwRtStBkReclnUpwdMovBossSwReq_Val: accessed-variable=SecRwRtStBkReclnUpwdMovBossSwReq.Val
            REC_SecRwRtStBkReclnUpwdMovBossSwReqV_Val: accessed-variable=SecRwRtStBkReclnUpwdMovBossSwReqV.Val
            REC_SecRwRtStBkwdMovBossSwReq_Val: accessed-variable=SecRwRtStBkwdMovBossSwReq.Val
            REC_SecRwRtStBkwdMovBossSwReqV_Val: accessed-variable=SecRwRtStBkwdMovBossSwReqV.Val
            REC_SecRwRtStFrwdMovBossSwReq_Val: accessed-variable=SecRwRtStFrwdMovBossSwReq.Val
            REC_SecRwRtStFrwdMovBossSwReqV_Val: accessed-variable=SecRwRtStFrwdMovBossSwReqV.Val
            REC_StSlctSwReq_Val: accessed-variable=StSlctSwReq.Val
            REC_StSlctSwReqV_Val: accessed-variable=StSlctSwReqV.Val
        data-send-points:
          6 x access:
            SEND_IfVeSMSbIs2LStSwAct_Val: accessed-variable=IfVeSMSbIs2LStSwAct.Val
            SEND_IfVeSMSbIs2RStSwAct_Val: accessed-variable=IfVeSMSbIs2RStSwAct.Val
            SEND_IfVeSMSbIs3LStSwAct_Val: accessed-variable=IfVeSMSbIs3LStSwAct.Val
            SEND_IfVeSMSbIs3RStSwAct_Val: accessed-variable=IfVeSMSbIs3RStSwAct.Val
            SEND_IfVeSMSbIsDrvStSwAct_Val: accessed-variable=IfVeSMSbIsDrvStSwAct.Val
            SEND_IfVeSMSbIsPasStSwAct_Val: accessed-variable=IfVeSMSbIsPasStSwAct.Val
  swc implementation SeatMdSwtchArbt_Implementation: behavior=SeatMdSwtchArbt_InternalBehavior
    code-descriptors:
      code Default: artifact-descriptors=autosar-engineering-object={short-label=Default, category=SWSRC}
package /PATAC/MSM/DataTypes/Implementation
  impl type SeatLmbrSwtchType: category=VALUE, base-type=UInt8, compu {0=CeSMS_LmbrNoAction, 1=CeSMS_LmbrFrwd, 2=CeSMS_LmbrBkwd, 3=CeSMS_LmbrUpwd, 4=CeSMS_LmbrDnwd, 255=CeSMS_LmbrFault; unit CompuMethods/NoUnit}, type-emitter=RTE
package /PATAC/MSM/DataTypes/ImplementationDataTypes
  6 x impl type, all with category=VALUE, base-type=UInt8:
    FwdBkwdMovmtVirtCtrlReq: compu {0=FwdBkwdVirtCtrlReq_NoReq, 1=Forward, 2=Backward; unit CompuMethods/NoUnit}
    OtwdInwdMovmtVirtCtrlReq: compu {0=OtwdInwdVirtCtrlReq_NoReq, 1=Outward, 2=Inward}
    TeSMS_e_DrvStMemSwAct: compu {0=CeSMS_e_Inactive, 1=CeSMS_e_Btn1SwtStorActv, 2=CeSMS_e_Btn1SwtRecallActv, 3=CeSMS_e_Btn2SwtStorActv, 4=CeSMS_e_Btn2SwtRecallActv, 5=CeSMS_e_BtnExitSwtStorActv, 6=CeSMS_e_BtnExitSwtRecallActv; unit Implementation/NoUnit}, range raw -INF..INF
    TeSMS_e_DrvStMemSwActV: compu {0=CeSMS_e_Valid, 1=CeSMS_e_Invalid; unit Implementation/NoUnit}, range raw -INF..INF
    TeSMS_e_SecLTSeatMemHMIReq: compu {0=CeSMS_e_NoAction, 1=CeSMS_e_Btn1StroReq, 2=CeSMS_e_Btn2StroReq, 3=CeSMS_e_Btn3StroReq, 4=CeSMS_e_Btn1RecallReq, 5=CeSMS_e_Btn2RecallReq, 6=CeSMS_e_Btn3RecallReq; unit Implementation/NoUnit}, range raw -INF..INF, type-emitter=RTE
    UpwdDnwdMovmtVirtCtrlReq: compu {0=UpwdDnwdVirtCtrlReq_NoReq, 1=Upward, 2=Downward; unit Implementation/NoUnit}
package /PATAC/MSM/ModeAdjust/DataType
  impl type LugSelectSw1: category=VALUE, base-type=UInt8, sw-calibration-access=READ-ONLY, compu {0=LugSelectSw_NoAction, 1=LugSelectSw_Left, 2=LugSelectSw_Right, 3=LugSelectSw_All}, type-emitter=RTE
  impl type PosRclRspStat1: category=VALUE, base-type=UInt8, sw-calibration-access=READ-ONLY, compu {0=PosRclRspStat_None, 1=PosRclRspStat_RecallSuccessfully, 2=PosRclRspStat_RecallUnsuccessfully, 3=PosRclRspStat_RecallOngoing}, type-emitter=RTE
package /PATAC/MSM/ModeAdjust/Interfaces
  8 x sender receiver interface:
    IfVeSMSbRrPsgComprtStBkReclnDnwdSwReq: invalidation-policy{data-element=IfVeSMSbRrPsgComprtStBkReclnDnwdSwReq/Val, handle-invalid=DONT-INVALIDATE}
      data Val: type=Boolean
    IfVeSMSbRrPsgComprtStBkReclnDnwdSwReqV: invalidation-policy{data-element=IfVeSMSbRrPsgComprtStBkReclnDnwdSwReqV/Val, handle-invalid=DONT-INVALIDATE}
      data Val: type=Boolean
    IfVeSMSbRrPsgComprtStBkReclnUpwdSwReq: invalidation-policy{data-element=IfVeSMSbRrPsgComprtStBkReclnUpwdSwReq/Val, handle-invalid=DONT-INVALIDATE}
      data Val: type=Boolean
    IfVeSMSbRrPsgComprtStBkReclnUpwdSwReqV: invalidation-policy{data-element=IfVeSMSbRrPsgComprtStBkReclnUpwdSwReqV/Val, handle-invalid=DONT-INVALIDATE}
      data Val: type=Boolean
    IfVeSMSbRrPsgComprtStBkwdSwReq: invalidation-policy{data-element=IfVeSMSbRrPsgComprtStBkwdSwReq/Val, handle-invalid=DONT-INVALIDATE}
      data Val: type=Boolean
    IfVeSMSbRrPsgComprtStBkwdSwReqV: invalidation-policy{data-element=IfVeSMSbRrPsgComprtStBkwdSwReqV/Val, handle-invalid=DONT-INVALIDATE}
      data Val: type=Boolean
    IfVeSMSbRrPsgComprtStFrwdSwReq: invalidation-policy{data-element=IfVeSMSbRrPsgComprtStFrwdSwReq/Val, handle-invalid=DONT-INVALIDATE}
      data Val: type=Boolean
    IfVeSMSbRrPsgComprtStFrwdSwReqV: invalidation-policy{data-element=IfVeSMSbRrPsgComprtStFrwdSwReqV/Val, handle-invalid=DONT-INVALIDATE}
      data Val: type=Boolean
package /PATAC/MSM/ModeAdjust/PortInterface
  21 x sender receiver interface:
    IfSecRwRtStZeroGrvyDnwdSwReq: invalidation-policy{data-element=IfSecRwRtStZeroGrvyDnwdSwReq/Val, handle-invalid=DONT-INVALIDATE}
      data Val: type=Boolean
    IfSecRwRtStZeroGrvyDnwdSwReqV: invalidation-policy{data-element=IfSecRwRtStZeroGrvyDnwdSwReqV/Val, handle-invalid=DONT-INVALIDATE}
      data Val: type=Boolean
    IfSecRwRtStZeroGrvyUpwdSwReq: invalidation-policy{data-element=IfSecRwRtStZeroGrvyUpwdSwReq/Val, handle-invalid=DONT-INVALIDATE}
      data Val: type=Boolean
    IfSecRwRtStZeroGrvyUpwdSwReqV: invalidation-policy{data-element=IfSecRwRtStZeroGrvyUpwdSwReqV/Val, handle-invalid=DONT-INVALIDATE}
      data Val: type=Boolean
    IfVeSMSbSecRwLtStArmScrnHMI2LReq: invalidation-policy{data-element=IfVeSMSbSecRwLtStArmScrnHMI2LReq/Val, handle-invalid=DONT-INVALIDATE}
      data Val: type=Boolean
    IfVeSMSbSecRwLtStFtClsHMI2LReq: invalidation-policy{data-element=IfVeSMSbSecRwLtStFtClsHMI2LReq/Val, handle-invalid=DONT-INVALIDATE}
      data Val: type=Boolean
    IfVeSMSbSecRwLtStFtOpenHMI2LReq: invalidation-policy{data-element=IfVeSMSbSecRwLtStFtOpenHMI2LReq/Val, handle-invalid=DONT-INVALIDATE}
      data Val: type=Boolean
    IfVeSMSbSecRwRtStArmScrnHMI2RReq: invalidation-policy{data-element=IfVeSMSbSecRwRtStArmScrnHMI2RReq/Val, handle-invalid=DONT-INVALIDATE}
      data Val: type=Boolean
    IfVeSMSbSecRwRtStFtClsHMI2LReq: invalidation-policy{data-element=IfVeSMSbSecRwRtStFtClsHMI2LReq/Val, handle-invalid=DONT-INVALIDATE}
      data Val: type=Boolean
    IfVeSMSbSecRwRtStFtOpenHMI2LReq: invalidation-policy{data-element=IfVeSMSbSecRwRtStFtOpenHMI2LReq/Val, handle-invalid=DONT-INVALIDATE}
      data Val: type=Boolean
    LugMdSelectSwt: invalidation-policy{data-element=LugMdSelectSwt/Val, handle-invalid=DONT-INVALIDATE}
      data Val: type=LugSelectSw1
    PosRclRspStat: invalidation-policy{data-element=PosRclRspStat/Val, handle-invalid=DONT-INVALIDATE}
      data Val: type=PosRclRspStat1
    SecRwRtStBkReclnDnwdMovBossSwReq: invalidation-policy{data-element=SecRwRtStBkReclnDnwdMovBossSwReq/Val, handle-invalid=DONT-INVALIDATE}
      data Val: type=Boolean
    SecRwRtStBkReclnDnwdMovBossSwReqV: invalidation-policy{data-element=SecRwRtStBkReclnDnwdMovBossSwReqV/Val, handle-invalid=DONT-INVALIDATE}
      data Val: type=Boolean
    SecRwRtStBkReclnUpwdMovBossSwReq: invalidation-policy{data-element=SecRwRtStBkReclnUpwdMovBossSwReq/Val, handle-invalid=DONT-INVALIDATE}
      data Val: type=Boolean
    SecRwRtStBkReclnUpwdMovBossSwReqV: invalidation-policy{data-element=SecRwRtStBkReclnUpwdMovBossSwReqV/Val, handle-invalid=DONT-INVALIDATE}
      data Val: type=Boolean
    SecRwRtStBkwdMovBossSwReq: invalidation-policy{data-element=SecRwRtStBkwdMovBossSwReq/Val, handle-invalid=DONT-INVALIDATE}
      data Val: type=Boolean
    SecRwRtStBkwdMovBossSwReqV: invalidation-policy{data-element=SecRwRtStBkwdMovBossSwReqV/Val, handle-invalid=DONT-INVALIDATE}
      data Val: type=Boolean
    SecRwRtStFrwdMovBossSwReq: invalidation-policy{data-element=SecRwRtStFrwdMovBossSwReq/Val, handle-invalid=DONT-INVALIDATE}
      data Val: type=Boolean
    SecRwRtStFrwdMovBossSwReqV: invalidation-policy{data-element=SecRwRtStFrwdMovBossSwReqV/Val, handle-invalid=DONT-INVALIDATE}
      data Val: type=Boolean
    Validity: invalidation-policy{data-element=Validity/Val, handle-invalid=DONT-INVALIDATE}
      data Val: type=Boolean
package /PATAC/MSM/PortInterfaces
  136 x sender receiver interface:
    IfDrvSeatMemSwtAct1: invalidation-policy{data-element=IfDrvSeatMemSwtAct1/Val, handle-invalid=DONT-INVALIDATE}
      data Val: type=TeSMS_e_DrvStMemSwAct
    IfDrvSeatMemSwtActV1: invalidation-policy{data-element=IfDrvSeatMemSwtActV1/Val, handle-invalid=DONT-INVALIDATE}
      data Val: type=TeSMS_e_DrvStMemSwActV
    IfSecRwLtStCushnFrtDnwdHMI2LReq: invalidation-policy{data-element=IfSecRwLtStCushnFrtDnwdHMI2LReq/Val, handle-invalid=DONT-INVALIDATE}
      data Val: type=Boolean
    IfSecRwLtStCushnFrtUpwdDnwdMovmtVirtCtrlReq: invalidation-policy{data-element=IfSecRwLtStCushnFrtUpwdDnwdMovmtVirtCtrlReq/Val, handle-invalid=DONT-INVALIDATE}
      data Val: type=UpwdDnwdMovmtVirtCtrlReq
    IfSecRwLtStCushnFrtUpwdHMI2LReq: invalidation-policy{data-element=IfSecRwLtStCushnFrtUpwdHMI2LReq/Val, handle-invalid=DONT-INVALIDATE}
      data Val: type=Boolean
    IfSecRwLtStFwdBkwdMovmtVirtCtrlReq: invalidation-policy{data-element=IfSecRwLtStFwdBkwdMovmtVirtCtrlReq/Val, handle-invalid=DONT-INVALIDATE}
      data Val: type=FwdBkwdMovmtVirtCtrlReq
    IfSecRwLtStLgrstOtwdInwdMovmtVirtCtrlReq: invalidation-policy{data-element=IfSecRwLtStLgrstOtwdInwdMovmtVirtCtrlReq/Val, handle-invalid=DONT-INVALIDATE}
      data Val: type=OtwdInwdMovmtVirtCtrlReq
    IfSecRwLtStLgrstUpwdDnwdMovmtVirtCtrlReq: invalidation-policy{data-element=IfSecRwLtStLgrstUpwdDnwdMovmtVirtCtrlReq/Val, handle-invalid=DONT-INVALIDATE}
      data Val: type=UpwdDnwdMovmtVirtCtrlReq
    IfSecRwLtStRclUpwdDnwdMovmtVirtCtrlReq: invalidation-policy{data-element=IfSecRwLtStRclUpwdDnwdMovmtVirtCtrlReq/Val, handle-invalid=DONT-INVALIDATE}
      data Val: type=UpwdDnwdMovmtVirtCtrlReq
    IfSecRwRtStCushnFrtDnwdHMI2LReq: invalidation-policy{data-element=IfSecRwRtStCushnFrtDnwdHMI2LReq/Val, handle-invalid=DONT-INVALIDATE}
      data Val: type=Boolean
    IfSecRwRtStCushnFrtUpwdDnwdMovmtVirtCtrlReq: invalidation-policy{data-element=IfSecRwRtStCushnFrtUpwdDnwdMovmtVirtCtrlReq/Val, handle-invalid=DONT-INVALIDATE}
      data Val: type=UpwdDnwdMovmtVirtCtrlReq
    IfSecRwRtStCushnFrtUpwdHMI2LReq: invalidation-policy{data-element=IfSecRwRtStCushnFrtUpwdHMI2LReq/Val, handle-invalid=DONT-INVALIDATE}
      data Val: type=Boolean
    IfSecRwRtStFwdBkwdMovmtVirtCtrlReq: invalidation-policy{data-element=IfSecRwRtStFwdBkwdMovmtVirtCtrlReq/Val, handle-invalid=DONT-INVALIDATE}
      data Val: type=FwdBkwdMovmtVirtCtrlReq
    IfSecRwRtStLgrstInwdSwReq: invalidation-policy{data-element=IfSecRwRtStLgrstInwdSwReq/Val, handle-invalid=DONT-INVALIDATE}
      data Val: type=Boolean
    IfSecRwRtStLgrstInwdSwReqV: invalidation-policy{data-element=IfSecRwRtStLgrstInwdSwReqV/Val, handle-invalid=DONT-INVALIDATE}
      data Val: type=Boolean
    IfSecRwRtStLgrstOtwdInwdMovmtVirtCtrlReq: invalidation-policy{data-element=IfSecRwRtStLgrstOtwdInwdMovmtVirtCtrlReq/Val, handle-invalid=DONT-INVALIDATE}
      data Val: type=OtwdInwdMovmtVirtCtrlReq
    IfSecRwRtStLgrstOtwdSwReq: invalidation-policy{data-element=IfSecRwRtStLgrstOtwdSwReq/Val, handle-invalid=DONT-INVALIDATE}
      data Val: type=Boolean
    IfSecRwRtStLgrstOtwdSwReqV: invalidation-policy{data-element=IfSecRwRtStLgrstOtwdSwReqV/Val, handle-invalid=DONT-INVALIDATE}
      data Val: type=Boolean
    IfSecRwRtStLgrstUpwdDnwdMovmtVirtCtrlReq: invalidation-policy{data-element=IfSecRwRtStLgrstUpwdDnwdMovmtVirtCtrlReq/Val, handle-invalid=DONT-INVALIDATE}
      data Val: type=UpwdDnwdMovmtVirtCtrlReq
    IfSecRwRtStRclUpwdDnwdMovmtVirtCtrlReq: invalidation-policy{data-element=IfSecRwRtStRclUpwdDnwdMovmtVirtCtrlReq/Val, handle-invalid=DONT-INVALIDATE}
      data Val: type=UpwdDnwdMovmtVirtCtrlReq
    IfVeSMSb_DrvStCshnRrDnwdMovSwAct: invalidation-policy{data-element=IfVeSMSb_DrvStCshnRrDnwdMovSwAct/Val, handle-invalid=DONT-INVALIDATE}
      data Val: type=Boolean
    IfVeSMSb_DrvStCshnRrDnwdMovSwActV: invalidation-policy{data-element=IfVeSMSb_DrvStCshnRrDnwdMovSwActV/Val, handle-invalid=DONT-INVALIDATE}
      data Val: type=Boolean
    IfVeSMSb2LSecRwStBkReclnDnwdSwActv: invalidation-policy{data-element=IfVeSMSb2LSecRwStBkReclnDnwdSwActv/Val, handle-invalid=DONT-INVALIDATE}
      data Val: type=boolean
    IfVeSMSb2LSecRwStBkReclnUpwdSwActv: invalidation-policy{data-element=IfVeSMSb2LSecRwStBkReclnUpwdSwActv/Val, handle-invalid=DONT-INVALIDATE}
      data Val: type=boolean
    IfVeSMSb2LSecRwStBkwdSwActv: invalidation-policy{data-element=IfVeSMSb2LSecRwStBkwdSwActv/Val, handle-invalid=DONT-INVALIDATE}
      data Val: type=boolean
    IfVeSMSb2LSecRwStFrwdSwActv: invalidation-policy{data-element=IfVeSMSb2LSecRwStFrwdSwActv/Val, handle-invalid=DONT-INVALIDATE}
      data Val: type=boolean
    IfVeSMSb2LSecRwStLgrstDnwdSwActv: invalidation-policy{data-element=IfVeSMSb2LSecRwStLgrstDnwdSwActv/Val, handle-invalid=DONT-INVALIDATE}
      data Val: type=boolean
    IfVeSMSb2LSecRwStLgrstUpwdSwActv: invalidation-policy{data-element=IfVeSMSb2LSecRwStLgrstUpwdSwActv/Val, handle-invalid=DONT-INVALIDATE}
      data Val: type=boolean
    IfVeSMSbBosSWBkwdHMI2RReq: invalidation-policy{data-element=IfVeSMSbBosSWBkwdHMI2RReq/Val, handle-invalid=DONT-INVALIDATE}
      data Val: type=Boolean
    IfVeSMSbBosSWFrwdHMI2RReq: invalidation-policy{data-element=IfVeSMSbBosSWFrwdHMI2RReq/Val, handle-invalid=DONT-INVALIDATE}
      data Val: type=Boolean
    IfVeSMSbBosSWStBkReclnDnwdHMI2RReq: invalidation-policy{data-element=IfVeSMSbBosSWStBkReclnDnwdHMI2RReq/Val, handle-invalid=DONT-INVALIDATE}
      data Val: type=Boolean
    IfVeSMSbBosSWStBkReclnUpwdHMI2RReq: invalidation-policy{data-element=IfVeSMSbBosSWStBkReclnUpwdHMI2RReq/Val, handle-invalid=DONT-INVALIDATE}
      data Val: type=Boolean
    IfVeSMSbDrvStBkReclnDnwdMovSwAct: invalidation-policy{data-element=IfVeSMSbDrvStBkReclnDnwdMovSwAct/Val, handle-invalid=DONT-INVALIDATE}
      data Val: type=Boolean
    IfVeSMSbDrvStBkReclnDnwdMovSwActV: invalidation-policy{data-element=IfVeSMSbDrvStBkReclnDnwdMovSwActV/Val, handle-invalid=DONT-INVALIDATE}
      data Val: type=Boolean
    IfVeSMSbDrvStBkReclnUpwdMovSwAct: invalidation-policy{data-element=IfVeSMSbDrvStBkReclnUpwdMovSwAct/Val, handle-invalid=DONT-INVALIDATE}
      data Val: type=Boolean
    IfVeSMSbDrvStBkReclnUpwdMovSwActV: invalidation-policy{data-element=IfVeSMSbDrvStBkReclnUpwdMovSwActV/Val, handle-invalid=DONT-INVALIDATE}
      data Val: type=Boolean
    IfVeSMSbDrvStBkwdMovSwAct: invalidation-policy{data-element=IfVeSMSbDrvStBkwdMovSwAct/Val, handle-invalid=DONT-INVALIDATE}
      data Val: type=Boolean
    IfVeSMSbDrvStBkwdMovSwActV: invalidation-policy{data-element=IfVeSMSbDrvStBkwdMovSwActV/Val, handle-invalid=DONT-INVALIDATE}
      data Val: type=Boolean
    IfVeSMSbDrvStCshnFrntDnwdMovSwAct: invalidation-policy{data-element=IfVeSMSbDrvStCshnFrntDnwdMovSwAct/Val, handle-invalid=DONT-INVALIDATE}
      data Val: type=Boolean
    IfVeSMSbDrvStCshnFrntDnwdMovSwActV: invalidation-policy{data-element=IfVeSMSbDrvStCshnFrntDnwdMovSwActV/Val, handle-invalid=DONT-INVALIDATE}
      data Val: type=Boolean
    IfVeSMSbDrvStCshnFrntUpwdMovSwAct: invalidation-policy{data-element=IfVeSMSbDrvStCshnFrntUpwdMovSwAct/Val, handle-invalid=DONT-INVALIDATE}
      data Val: type=Boolean
    IfVeSMSbDrvStCshnFrntUpwdMovSwActV: invalidation-policy{data-element=IfVeSMSbDrvStCshnFrntUpwdMovSwActV/Val, handle-invalid=DONT-INVALIDATE}
      data Val: type=Boolean
    IfVeSMSbDrvStCshnRrUpwdMovSwAct: invalidation-policy{data-element=IfVeSMSbDrvStCshnRrUpwdMovSwAct/Val, handle-invalid=DONT-INVALIDATE}
      data Val: type=Boolean
    IfVeSMSbDrvStCshnRrUpwdMovSwActV: invalidation-policy{data-element=IfVeSMSbDrvStCshnRrUpwdMovSwActV/Val, handle-invalid=DONT-INVALIDATE}
      data Val: type=Boolean
    IfVeSMSbDrvStFrwdMovSwAct: invalidation-policy{data-element=IfVeSMSbDrvStFrwdMovSwAct/Val, handle-invalid=DONT-INVALIDATE}
      data Val: type=Boolean
    IfVeSMSbDrvStFrwdMovSwActV: invalidation-policy{data-element=IfVeSMSbDrvStFrwdMovSwActV/Val, handle-invalid=DONT-INVALIDATE}
      data Val: type=Boolean
    IfVeSMSbPassStBkReclnDnwdMovBosSwAct: invalidation-policy{data-element=IfVeSMSbPassStBkReclnDnwdMovBosSwAct/Val, handle-invalid=DONT-INVALIDATE}
      data Val: type=Boolean
    IfVeSMSbPassStBkReclnDnwdMovBosSwActV: invalidation-policy{data-element=IfVeSMSbPassStBkReclnDnwdMovBosSwActV/Val, handle-invalid=DONT-INVALIDATE}
      data Val: type=Boolean
    IfVeSMSbPassStBkReclnDnwdMovSwAct: invalidation-policy{data-element=IfVeSMSbPassStBkReclnDnwdMovSwAct/Val, handle-invalid=DONT-INVALIDATE}
      data Val: type=Boolean
    IfVeSMSbPassStBkReclnDnwdMovSwActV: invalidation-policy{data-element=IfVeSMSbPassStBkReclnDnwdMovSwActV/Val, handle-invalid=DONT-INVALIDATE}
      data Val: type=Boolean
    IfVeSMSbPassStBkReclnUpwdMovBosSwAct: invalidation-policy{data-element=IfVeSMSbPassStBkReclnUpwdMovBosSwAct/Val, handle-invalid=DONT-INVALIDATE}
      data Val: type=Boolean
    IfVeSMSbPassStBkReclnUpwdMovBosSwActV: invalidation-policy{data-element=IfVeSMSbPassStBkReclnUpwdMovBosSwActV/Val, handle-invalid=DONT-INVALIDATE}
      data Val: type=Boolean
    IfVeSMSbPassStBkReclnUpwdMovSwAct: invalidation-policy{data-element=IfVeSMSbPassStBkReclnUpwdMovSwAct/Val, handle-invalid=DONT-INVALIDATE}
      data Val: type=Boolean
    IfVeSMSbPassStBkReclnUpwdMovSwActV: invalidation-policy{data-element=IfVeSMSbPassStBkReclnUpwdMovSwActV/Val, handle-invalid=DONT-INVALIDATE}
      data Val: type=Boolean
    IfVeSMSbPassStBkwdMovBosSwAct: invalidation-policy{data-element=IfVeSMSbPassStBkwdMovBosSwAct/Val, handle-invalid=DONT-INVALIDATE}
      data Val: type=Boolean
    IfVeSMSbPassStBkwdMovBosSwActV: invalidation-policy{data-element=IfVeSMSbPassStBkwdMovBosSwActV/Val, handle-invalid=DONT-INVALIDATE}
      data Val: type=Boolean
    IfVeSMSbPassStBkwdMovSwAct: invalidation-policy{data-element=IfVeSMSbPassStBkwdMovSwAct/Val, handle-invalid=DONT-INVALIDATE}
      data Val: type=Boolean
    IfVeSMSbPassStBkwdMovSwActV: invalidation-policy{data-element=IfVeSMSbPassStBkwdMovSwActV/Val, handle-invalid=DONT-INVALIDATE}
      data Val: type=Boolean
    IfVeSMSbPassStCshnFrntDnwdMovSwAct: invalidation-policy{data-element=IfVeSMSbPassStCshnFrntDnwdMovSwAct/Val, handle-invalid=DONT-INVALIDATE}
      data Val: type=Boolean
    IfVeSMSbPassStCshnFrntDnwdMovSwActV: invalidation-policy{data-element=IfVeSMSbPassStCshnFrntDnwdMovSwActV/Val, handle-invalid=DONT-INVALIDATE}
      data Val: type=Boolean
    IfVeSMSbPassStCshnFrntUpwdMovSwAct: invalidation-policy{data-element=IfVeSMSbPassStCshnFrntUpwdMovSwAct/Val, handle-invalid=DONT-INVALIDATE}
      data Val: type=Boolean
    IfVeSMSbPassStCshnFrntUpwdMovSwActV: invalidation-policy{data-element=IfVeSMSbPassStCshnFrntUpwdMovSwActV/Val, handle-invalid=DONT-INVALIDATE}
      data Val: type=Boolean
    IfVeSMSbPassStCshnRrDnwdMovSwAct: invalidation-policy{data-element=IfVeSMSbPassStCshnRrDnwdMovSwAct/Val, handle-invalid=DONT-INVALIDATE}
      data Val: type=Boolean
    IfVeSMSbPassStCshnRrDnwdMovSwActV: invalidation-policy{data-element=IfVeSMSbPassStCshnRrDnwdMovSwActV/Val, handle-invalid=DONT-INVALIDATE}
      data Val: type=Boolean
    IfVeSMSbPassStCshnRrUpwdMovSwAct: invalidation-policy{data-element=IfVeSMSbPassStCshnRrUpwdMovSwAct/Val, handle-invalid=DONT-INVALIDATE}
      data Val: type=Boolean
    IfVeSMSbPassStCshnRrUpwdMovSwActV: invalidation-policy{data-element=IfVeSMSbPassStCshnRrUpwdMovSwActV/Val, handle-invalid=DONT-INVALIDATE}
      data Val: type=Boolean
    IfVeSMSbPassStFrwdMovBosSwAct: invalidation-policy{data-element=IfVeSMSbPassStFrwdMovBosSwAct/Val, handle-invalid=DONT-INVALIDATE}
      data Val: type=Boolean
    IfVeSMSbPassStFrwdMovBosSwActV: invalidation-policy{data-element=IfVeSMSbPassStFrwdMovBosSwActV/Val, handle-invalid=DONT-INVALIDATE}
      data Val: type=Boolean
    IfVeSMSbPassStFrwdMovSwAct: invalidation-policy{data-element=IfVeSMSbPassStFrwdMovSwAct/Val, handle-invalid=DONT-INVALIDATE}
      data Val: type=Boolean
    IfVeSMSbPassStFrwdMovSwActV: invalidation-policy{data-element=IfVeSMSbPassStFrwdMovSwActV/Val, handle-invalid=DONT-INVALIDATE}
      data Val: type=Boolean
    IfVeSMSbSecRwLtStBkReclnDnwdHMI2LReq: invalidation-policy{data-element=IfVeSMSbSecRwLtStBkReclnDnwdHMI2LReq/Val, handle-invalid=DONT-INVALIDATE}
      data Val: type=boolean
    IfVeSMSbSecRwLtStBkReclnUpwdHMI2LReq: invalidation-policy{data-element=IfVeSMSbSecRwLtStBkReclnUpwdHMI2LReq/Val, handle-invalid=DONT-INVALIDATE}
      data Val: type=boolean
    IfVeSMSbSecRwLtStBkwdHMI2LReq: invalidation-policy{data-element=IfVeSMSbSecRwLtStBkwdHMI2LReq/Val, handle-invalid=DONT-INVALIDATE}
      data Val: type=boolean
    IfVeSMSbSecRwLtStFrwdHMI2LReq: invalidation-policy{data-element=IfVeSMSbSecRwLtStFrwdHMI2LReq/Val, handle-invalid=DONT-INVALIDATE}
      data Val: type=boolean
    IfVeSMSbSecRwLtStFtDnwdHMI2LReq: invalidation-policy{data-element=IfVeSMSbSecRwLtStFtDnwdHMI2LReq/Val, handle-invalid=DONT-INVALIDATE}
      data Val: type=Boolean
    IfVeSMSbSecRwLtStFtUpwdHMI2LReq: invalidation-policy{data-element=IfVeSMSbSecRwLtStFtUpwdHMI2LReq/Val, handle-invalid=DONT-INVALIDATE}
      data Val: type=Boolean
    IfVeSMSbSecRwLtStHdrstDnwdHMI2LReq: invalidation-policy{data-element=IfVeSMSbSecRwLtStHdrstDnwdHMI2LReq/Val, handle-invalid=DONT-INVALIDATE}
      data Val: type=boolean
    IfVeSMSbSecRwLtStHdrstUpwdHMI2LReq: invalidation-policy{data-element=IfVeSMSbSecRwLtStHdrstUpwdHMI2LReq/Val, handle-invalid=DONT-INVALIDATE}
      data Val: type=boolean
    IfVeSMSbSecRwLtStLcMovActv: invalidation-policy{data-element=IfVeSMSbSecRwLtStLcMovActv/Val, handle-invalid=DONT-INVALIDATE}
      data Val: type=Boolean
    IfVeSMSbSecRwLtStLgrstDnwdHMI2LReq: invalidation-policy{data-element=IfVeSMSbSecRwLtStLgrstDnwdHMI2LReq/Val, handle-invalid=DONT-INVALIDATE}
      data Val: type=boolean
    IfVeSMSbSecRwLtStLgrstUpwdHMI2LReq: invalidation-policy{data-element=IfVeSMSbSecRwLtStLgrstUpwdHMI2LReq/Val, handle-invalid=DONT-INVALIDATE}
      data Val: type=boolean
    IfVeSMSbSecRwLtStLtwdHMI2LReq: invalidation-policy{data-element=IfVeSMSbSecRwLtStLtwdHMI2LReq/Val, handle-invalid=DONT-INVALIDATE}
      data Val: type=boolean
    IfVeSMSbSecRwLtStRtwdHMI2LReq: invalidation-policy{data-element=IfVeSMSbSecRwLtStRtwdHMI2LReq/Val, handle-invalid=DONT-INVALIDATE}
      data Val: type=boolean
    IfVeSMSbSecRwRtStBkReclnDnwdHMI2RReq: invalidation-policy{data-element=IfVeSMSbSecRwRtStBkReclnDnwdHMI2RReq/Val, handle-invalid=DONT-INVALIDATE}
      data Val: type=Boolean
    IfVeSMSbSecRwRtStBkReclnDnwdSwReq: invalidation-policy{data-element=IfVeSMSbSecRwRtStBkReclnDnwdSwReq/Val, handle-invalid=DONT-INVALIDATE}
      data Val: type=Boolean
    IfVeSMSbSecRwRtStBkReclnDnwdSwReqV: invalidation-policy{data-element=IfVeSMSbSecRwRtStBkReclnDnwdSwReqV/Val, handle-invalid=DONT-INVALIDATE}
      data Val: type=Boolean
    IfVeSMSbSecRwRtStBkReclnUpwdHMI2RReq: invalidation-policy{data-element=IfVeSMSbSecRwRtStBkReclnUpwdHMI2RReq/Val, handle-invalid=DONT-INVALIDATE}
      data Val: type=Boolean
    IfVeSMSbSecRwRtStBkReclnUpwdSwReq: invalidation-policy{data-element=IfVeSMSbSecRwRtStBkReclnUpwdSwReq/Val, handle-invalid=DONT-INVALIDATE}
      data Val: type=Boolean
    IfVeSMSbSecRwRtStBkReclnUpwdSwReqV: invalidation-policy{data-element=IfVeSMSbSecRwRtStBkReclnUpwdSwReqV/Val, handle-invalid=DONT-INVALIDATE}
      data Val: type=Boolean
    IfVeSMSbSecRwRtStBkwdHMI2RReq: invalidation-policy{data-element=IfVeSMSbSecRwRtStBkwdHMI2RReq/Val, handle-invalid=DONT-INVALIDATE}
      data Val: type=Boolean
    IfVeSMSbSecRwRtStBkwdSwReq: invalidation-policy{data-element=IfVeSMSbSecRwRtStBkwdSwReq/Val, handle-invalid=DONT-INVALIDATE}
      data Val: type=Boolean
    IfVeSMSbSecRwRtStBkwdSwReqV: invalidation-policy{data-element=IfVeSMSbSecRwRtStBkwdSwReqV/Val, handle-invalid=DONT-INVALIDATE}
      data Val: type=Boolean
    IfVeSMSbSecRwRtStFrwdHMI2RReq: invalidation-policy{data-element=IfVeSMSbSecRwRtStFrwdHMI2RReq/Val, handle-invalid=DONT-INVALIDATE}
      data Val: type=Boolean
    IfVeSMSbSecRwRtStFrwdSwReq: invalidation-policy{data-element=IfVeSMSbSecRwRtStFrwdSwReq/Val, handle-invalid=DONT-INVALIDATE}
      data Val: type=Boolean
    IfVeSMSbSecRwRtStFrwdSwReqV: invalidation-policy{data-element=IfVeSMSbSecRwRtStFrwdSwReqV/Val, handle-invalid=DONT-INVALIDATE}
      data Val: type=Boolean
    IfVeSMSbSecRwRtStFtDnwdHMI2RReq: invalidation-policy{data-element=IfVeSMSbSecRwRtStFtDnwdHMI2RReq/Val, handle-invalid=DONT-INVALIDATE}
      data Val: type=Boolean
    IfVeSMSbSecRwRtStFtUpwdHMI2RReq: invalidation-policy{data-element=IfVeSMSbSecRwRtStFtUpwdHMI2RReq/Val, handle-invalid=DONT-INVALIDATE}
      data Val: type=Boolean
    IfVeSMSbSecRwRtStHdrstDnwdHMI2RReq: invalidation-policy{data-element=IfVeSMSbSecRwRtStHdrstDnwdHMI2RReq/Val, handle-invalid=DONT-INVALIDATE}
      data Val: type=Boolean
    IfVeSMSbSecRwRtStHdrstUpwdHMI2RReq: invalidation-policy{data-element=IfVeSMSbSecRwRtStHdrstUpwdHMI2RReq/Val, handle-invalid=DONT-INVALIDATE}
      data Val: type=Boolean
    IfVeSMSbSecRwRtStLgrstDnwdHMI2RReq: invalidation-policy{data-element=IfVeSMSbSecRwRtStLgrstDnwdHMI2RReq/Val, handle-invalid=DONT-INVALIDATE}
      data Val: type=Boolean
    IfVeSMSbSecRwRtStLgrstDnwdSwReq: invalidation-policy{data-element=IfVeSMSbSecRwRtStLgrstDnwdSwReq/Val, handle-invalid=DONT-INVALIDATE}
      data Val: type=Boolean
    IfVeSMSbSecRwRtStLgrstDnwdSwReqV: invalidation-policy{data-element=IfVeSMSbSecRwRtStLgrstDnwdSwReqV/Val, handle-invalid=DONT-INVALIDATE}
      data Val: type=Boolean
    IfVeSMSbSecRwRtStLgrstUpwdHMI2RReq: invalidation-policy{data-element=IfVeSMSbSecRwRtStLgrstUpwdHMI2RReq/Val, handle-invalid=DONT-INVALIDATE}
      data Val: type=Boolean
    IfVeSMSbSecRwRtStLgrstUpwdSwReq: invalidation-policy{data-element=IfVeSMSbSecRwRtStLgrstUpwdSwReq/Val, handle-invalid=DONT-INVALIDATE}
      data Val: type=Boolean
    IfVeSMSbSecRwRtStLgrstUpwdSwReqV: invalidation-policy{data-element=IfVeSMSbSecRwRtStLgrstUpwdSwReqV/Val, handle-invalid=DONT-INVALIDATE}
      data Val: type=Boolean
    IfVeSMSbSecRwRtStLmbrHMI2RReq: invalidation-policy{data-element=IfVeSMSbSecRwRtStLmbrHMI2RReq/Val, handle-invalid=DONT-INVALIDATE}
      data Val: type=SeatLmbrSwtchType
    IfVeSMSbSecRwRtStLtwdHMI2RReq: invalidation-policy{data-element=IfVeSMSbSecRwRtStLtwdHMI2RReq/Val, handle-invalid=DONT-INVALIDATE}
      data Val: type=Boolean
    IfVeSMSbSecRwRtStRtwdHMI2RReq: invalidation-policy{data-element=IfVeSMSbSecRwRtStRtwdHMI2RReq/Val, handle-invalid=DONT-INVALIDATE}
      data Val: type=Boolean
    IfVeSMSbThdRLtStExpdSwReq: invalidation-policy{data-element=IfVeSMSbThdRLtStExpdSwReq/Val, handle-invalid=DONT-INVALIDATE}
      data Val: type=Boolean
    IfVeSMSbThdRLtStExpdSwReqV: invalidation-policy{data-element=IfVeSMSbThdRLtStExpdSwReqV/Val, handle-invalid=DONT-INVALIDATE}
      data Val: type=Boolean
    IfVeSMSbThdRRtStExpdSwReq: invalidation-policy{data-element=IfVeSMSbThdRRtStExpdSwReq/Val, handle-invalid=DONT-INVALIDATE}
      data Val: type=Boolean
    IfVeSMSbThdRRtStExpdSwReqV: invalidation-policy{data-element=IfVeSMSbThdRRtStExpdSwReqV/Val, handle-invalid=DONT-INVALIDATE}
      data Val: type=Boolean
    IfVeSMSbThdRwLtStBkReclnDnwdSwReq: invalidation-policy{data-element=IfVeSMSbThdRwLtStBkReclnDnwdSwReq/Val, handle-invalid=DONT-INVALIDATE}
      data Val: type=Boolean
    IfVeSMSbThdRwLtStBkReclnDnwdSwReqV: invalidation-policy{data-element=IfVeSMSbThdRwLtStBkReclnDnwdSwReqV/Val, handle-invalid=DONT-INVALIDATE}
      data Val: type=Boolean
    IfVeSMSbThdRwLtStBkReclnUpwdSwReq: invalidation-policy{data-element=IfVeSMSbThdRwLtStBkReclnUpwdSwReq/Val, handle-invalid=DONT-INVALIDATE}
      data Val: type=Boolean
    IfVeSMSbThdRwLtStBkReclnUpwdSwReqV: invalidation-policy{data-element=IfVeSMSbThdRwLtStBkReclnUpwdSwReqV/Val, handle-invalid=DONT-INVALIDATE}
      data Val: type=Boolean
    IfVeSMSbThdRwLtStBkwdSwReq: invalidation-policy{data-element=IfVeSMSbThdRwLtStBkwdSwReq/Val, handle-invalid=DONT-INVALIDATE}
      data Val: type=Boolean
    IfVeSMSbThdRwLtStBkwdSwReqV: invalidation-policy{data-element=IfVeSMSbThdRwLtStBkwdSwReqV/Val, handle-invalid=DONT-INVALIDATE}
      data Val: type=Boolean
    IfVeSMSbThdRwLtStFrwdSwReq: invalidation-policy{data-element=IfVeSMSbThdRwLtStFrwdSwReq/Val, handle-invalid=DONT-INVALIDATE}
      data Val: type=Boolean
    IfVeSMSbThdRwLtStFrwdSwReqV: invalidation-policy{data-element=IfVeSMSbThdRwLtStFrwdSwReqV/Val, handle-invalid=DONT-INVALIDATE}
      data Val: type=Boolean
    IfVeSMSbThdRwRtStBkReclnDnwdSwReq: invalidation-policy{data-element=IfVeSMSbThdRwRtStBkReclnDnwdSwReq/Val, handle-invalid=DONT-INVALIDATE}
      data Val: type=Boolean
    IfVeSMSbThdRwRtStBkReclnDnwdSwReqV: invalidation-policy{data-element=IfVeSMSbThdRwRtStBkReclnDnwdSwReqV/Val, handle-invalid=DONT-INVALIDATE}
      data Val: type=Boolean
    IfVeSMSbThdRwRtStBkReclnUpwdSwReq: invalidation-policy{data-element=IfVeSMSbThdRwRtStBkReclnUpwdSwReq/Val, handle-invalid=DONT-INVALIDATE}
      data Val: type=Boolean
    IfVeSMSbThdRwRtStBkReclnUpwdSwReqV: invalidation-policy{data-element=IfVeSMSbThdRwRtStBkReclnUpwdSwReqV/Val, handle-invalid=DONT-INVALIDATE}
      data Val: type=Boolean
    IfVeSMSbThdRwRtStBkwdSwReq: invalidation-policy{data-element=IfVeSMSbThdRwRtStBkwdSwReq/Val, handle-invalid=DONT-INVALIDATE}
      data Val: type=Boolean
    IfVeSMSbThdRwRtStBkwdSwReqV: invalidation-policy{data-element=IfVeSMSbThdRwRtStBkwdSwReqV/Val, handle-invalid=DONT-INVALIDATE}
      data Val: type=Boolean
    IfVeSMSbThdRwRtStFrwdSwReq: invalidation-policy{data-element=IfVeSMSbThdRwRtStFrwdSwReq/Val, handle-invalid=DONT-INVALIDATE}
      data Val: type=Boolean
    IfVeSMSbThdRwRtStFrwdSwReqV: invalidation-policy{data-element=IfVeSMSbThdRwRtStFrwdSwReqV/Val, handle-invalid=DONT-INVALIDATE}
      data Val: type=Boolean
    IfVeSMSeSecLTMemHMI2LReq1: invalidation-policy{data-element=IfVeSMSeSecLTMemHMI2LReq1/Val, handle-invalid=DONT-INVALIDATE}
      data Val: type=TeSMS_e_SecLTSeatMemHMIReq
    IfVeSMSeSecLTMemHMI2RReq1: invalidation-policy{data-element=IfVeSMSeSecLTMemHMI2RReq1/Val, handle-invalid=DONT-INVALIDATE}
      data Val: type=TeSMS_e_SecLTSeatMemHMIReq
    IfVeSMSuSeatPosEnable: invalidation-policy{data-element=IfVeSMSuSeatPosEnable/Val, handle-invalid=DONT-INVALIDATE}
      data Val: type=UInt8
    SeatHMIReq: invalidation-policy{data-element=SeatHMIReq/Val, handle-invalid=DONT-INVALIDATE}
      data Val: type=Boolean
    SeatPosV: invalidation-policy{data-element=SeatPosV/Val, handle-invalid=DONT-INVALIDATE}
      data Val: type=Boolean
    SeatSwReq: invalidation-policy{data-element=SeatSwReq/Val, handle-invalid=DONT-INVALIDATE}
      data Val: type=UInt8
    SeatSwReqV: invalidation-policy{data-element=SeatSwReqV/Val, handle-invalid=DONT-INVALIDATE}
      data Val: type=Boolean
    TrgtPos: invalidation-policy{data-element=TrgtPos/Val, handle-invalid=DONT-INVALIDATE}
      data Val: type=UInt16
package /PATAC/VSM/DataTypes/CompuMethods
  compu method COMPU_boolean: 0=FALSE, 1=TRUE; unit CompuMethods/NoUnit
  unit NoUnit: factor-si-to-unit=1, offset-si-to-unit=0
package /PortInterfaces
  sender receiver interface SeatSwActive: invalidation-policy{data-element=SeatSwActive/Val, handle-invalid=DONT-INVALIDATE}
    data Val: type=Boolean
